[part 1 of 2: packages /Diagnostics/port_interfaces to /DataTypes/ImplementationDataTypes]
AUTOSAR XML (schema 00047)
standard types defined: boolean, uint16, uint32, uint64, uint8
package /Diagnostics/port_interfaces
  diagnostic condition interface Condition_Interface
  diagnostic dtc information interface DTC_Information_Interface
  diagnostic data identifier generic interface DataIdentifierGeneric_Interface
  diagnostic data identifier interface VersionInfoDataIdentifier
    namespaces:
      symbol props lorem
      symbol props ipsum
    read Read
      arg VersionInfoBuffer: type=ByteVector, direction=OUT
  diagnostic data identifier interface SystemInfoDataIdentifier
    namespaces:
      symbol props lorem
      symbol props ipsum
    read Read
      arg SystemInfoBuffer: type=ByteVector, direction=OUT
  diagnostic data identifier interface VINInformation_Interface
    read Read
      arg Vin: type=VINType, direction=OUT
    write Write
      arg Vin: type=VINType, direction=IN
  diagnostic do ip group identification interface DoIPGroupIdentification_Interface
  diagnostic do ip power mode interface DoIPPowerMode_Interface
  diagnostic download interface Download_Interface
  diagnostic event interface Event_Interface
  diagnostic generic uds interface Generic_Uds_Interface
  diagnostic indicator interface Indicator_Interface
  diagnostic monitor interface Monitor_Interface
  diagnostic operation cycle interface OperationCycle_Interface
  diagnostic routine generic interface RoutineGeneric_Interface
  diagnostic security level interface SecurityLevel_Interface
  diagnostic service validation interface ServiceValidation_Interface
  diagnostic upload interface Upload_Interface
package /Diagnostics/types
  11 x std cpp implementation data type, all with type-emitter=TYPE_EMITTER_ARA:
    VINType: category=ARRAY, array-size=17, cpp-template-argument=uint8_t  # 17 byte array of uint8 representing the VIN
      namespaces:
        symbol props ara
        symbol props diag
    ArrayBytes7: category=ARRAY, array-size=7, cpp-template-argument=uint8_t  # byte array of 7 bytes
      namespaces:
        symbol props self_diag_agent
    ByteVector: category=VECTOR, cpp-template-argument=uint8_t  # Vector of uint8
      namespaces:
        symbol props self_diag_agent
    InstanceHandle: type-reference=uint32_t
      namespaces:
        symbol props ns0: symbol=amsr
        symbol props ns1: symbol=diag
        symbol props ns2: symbol=com_api
    DiagRequestType: category=STRUCTURE
      namespaces:
        symbol props ns0: symbol=amsr
        symbol props ns1: symbol=diag
        symbol props ns2: symbol=com_api
      5 x cpp implementation data type element:
        handle: type-reference=HandleType
        instance_handle: type-reference=InstanceHandle
        conversation_handle: type-reference=ConversationHandle
        job_identifier: type-reference=JobIdentifier
        value: type-reference=ByteVectorType
    ConversationHandle: type-reference=uint16_t
      namespaces:
        symbol props ns0: symbol=amsr
        symbol props ns1: symbol=diag
        symbol props ns2: symbol=com_api
    HandleType: type-reference=uint16_t
      namespaces:
        symbol props ns0: symbol=amsr
        symbol props ns1: symbol=diag
        symbol props ns2: symbol=com_api
    MetaInfoType: category=ASSOCIATIVE_MAP, template-arguments=[string, string]  # Meta-Inf map, which contains key-value pairs of MetaInfoKeyType, MetaInfoValueType.
      namespaces:
        symbol props ns0: symbol=amsr
        symbol props ns1: symbol=diag
        symbol props ns2: symbol=com_api
    ByteVectorType: category=VECTOR, cpp-template-argument=uint8_t
      namespaces:
        symbol props ns0: symbol=amsr
        symbol props ns1: symbol=diag
        symbol props ns2: symbol=com_api
    JobIdentifier: type-reference=uint32_t
      namespaces:
        symbol props ns0: symbol=amsr
        symbol props ns1: symbol=diag
        symbol props ns2: symbol=com_api
    DaemonRequestResponseType: category=STRUCTURE
      namespaces:
        symbol props ns0: symbol=amsr
        symbol props ns1: symbol=diag
        symbol props ns2: symbol=com_api
      cpp implementation data type element response_type: type-reference=HandleType
      cpp implementation data type element job_identifier: type-reference=JobIdentifier
      cpp implementation data type element value: type-reference=ByteVectorType
package /Diagnostics/Persistency
  persistency file array Deamon_PersistencyFileArray: update-strategy=KEEP-EXISTING, uri=./etc/nv_data
  persistency file proxy interface PersistencyInterface: category=binary
  persistency port prototype to file array mapping PersistencyPortPrototypeToFileArrayMapping: persistency-file-array=Deamon_PersistencyFileArray, port-prototype=BaseApplicationExecutableRootSwc.Persistency, process=DiagnosticManagerDeamon
package /Application/AdaptiveApplicationSwComponentTypes
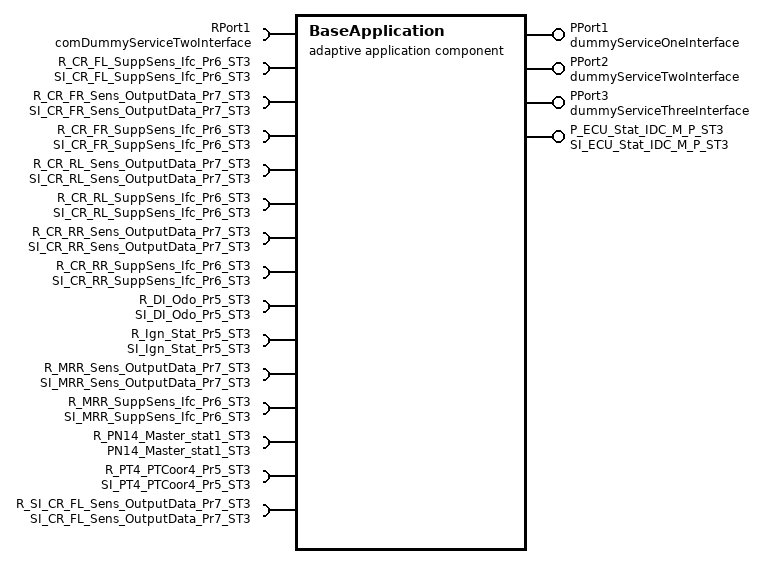
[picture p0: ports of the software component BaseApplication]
  adaptive application sw component type BaseApplication
    4 x provide port:
      PPort1: provided-interface=dummyServiceOneInterface
      PPort2: provided-interface=dummyServiceTwoInterface
      PPort3: provided-interface=dummyServiceThreeInterface
      P_ECU_Stat_IDC_M_P_ST3: provided-interface=SI_ECU_Stat_IDC_M_P_ST3
    provide/require port MyPersistencyKvsPrPortPrototype: provided-required-interface=IF_Persistency_KVS
    15 x require port:
      RPort1: required-interface=comDummyServiceTwoInterface
      R_CR_FL_SuppSens_Ifc_Pr6_ST3: required-interface=SI_CR_FL_SuppSens_Ifc_Pr6_ST3
      R_CR_FR_Sens_OutputData_Pr7_ST3: required-interface=SI_CR_FR_Sens_OutputData_Pr7_ST3
      R_CR_FR_SuppSens_Ifc_Pr6_ST3: required-interface=SI_CR_FR_SuppSens_Ifc_Pr6_ST3
      R_CR_RL_Sens_OutputData_Pr7_ST3: required-interface=SI_CR_RL_Sens_OutputData_Pr7_ST3
      R_CR_RL_SuppSens_Ifc_Pr6_ST3: required-interface=SI_CR_RL_SuppSens_Ifc_Pr6_ST3
      R_CR_RR_Sens_OutputData_Pr7_ST3: required-interface=SI_CR_RR_Sens_OutputData_Pr7_ST3
      R_CR_RR_SuppSens_Ifc_Pr6_ST3: required-interface=SI_CR_RR_SuppSens_Ifc_Pr6_ST3
      R_DI_Odo_Pr5_ST3: required-interface=SI_DI_Odo_Pr5_ST3
      R_Ign_Stat_Pr5_ST3: required-interface=SI_Ign_Stat_Pr5_ST3
      R_MRR_Sens_OutputData_Pr7_ST3: required-interface=SI_MRR_Sens_OutputData_Pr7_ST3
      R_MRR_SuppSens_Ifc_Pr6_ST3: required-interface=SI_MRR_SuppSens_Ifc_Pr6_ST3
      R_PN14_Master_stat1_ST3: required-interface=PN14_Master_stat1_ST3
      R_PT4_PTCoor4_Pr5_ST3: required-interface=SI_PT4_PTCoor4_Pr5_ST3
      R_SI_CR_FL_Sens_OutputData_Pr7_ST3: required-interface=SI_CR_FL_Sens_OutputData_Pr7_ST3
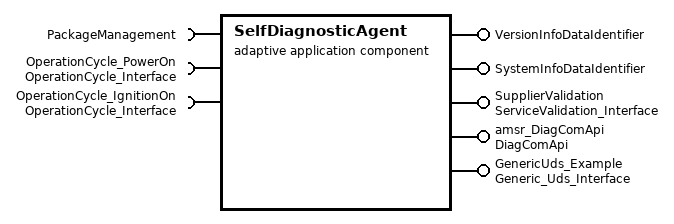
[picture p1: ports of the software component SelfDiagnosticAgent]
  adaptive application sw component type SelfDiagnosticAgent
    5 x provide port:
      VersionInfoDataIdentifier: provided-interface=VersionInfoDataIdentifier
      SystemInfoDataIdentifier: provided-interface=SystemInfoDataIdentifier
      SupplierValidation: provided-interface=ServiceValidation_Interface
      amsr_DiagComApi: provided-interface=DiagComApi
      GenericUds_Example: provided-interface=Generic_Uds_Interface
    require port PackageManagement: required-interface=PackageManagement
    require port OperationCycle_PowerOn: required-interface=OperationCycle_Interface
    require port OperationCycle_IgnitionOn: required-interface=OperationCycle_Interface
    adaptive swc internal behavior AdaptiveInternalBehavior
      6 x swc service dependency:
        SwcDependency_VersionInfoDataIdentifier_Port: assigned-ports=role-based-port-assignment={port-prototype=VersionInfoDataIdentifier, role=DataServices}
        SwcDependency_SystemInfoDataIdentifier_Port: assigned-ports=role-based-port-assignment={port-prototype=SystemInfoDataIdentifier, role=DataServices}
        OperationCyclePowerOn: assigned-ports=role-based-port-assignment={port-prototype=OperationCycle_PowerOn, role=SomeOtherRole}
        OperationCycleIgnitionOn: assigned-ports=role-based-port-assignment={port-prototype=OperationCycle_IgnitionOn, role=SomeOtherRole}
        SwcDependency_ServiceValidation_Supplier_Example: assigned-ports=role-based-port-assignment={port-prototype=SupplierValidation, role=ServiceValidation}
          service-needs:
            diagnostic communication manager needs Supplier: service-request-callback-type=REQUEST-CALLBACK-TYPE-SUPPLIER
        GenericUds_Example: assigned-ports=role-based-port-assignment={port-prototype=GenericUds_Example, role=SomeOtherRole}
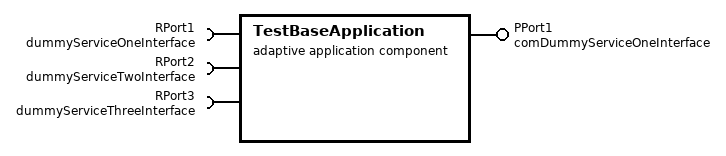
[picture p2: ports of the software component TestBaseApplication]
  adaptive application sw component type TestBaseApplication
    provide port PPort1: provided-interface=comDummyServiceOneInterface
    require port RPort1: required-interface=dummyServiceOneInterface
    require port RPort2: required-interface=dummyServiceTwoInterface
    require port RPort3: required-interface=dummyServiceThreeInterface
package /Application/Executables
  4 x executable, all with category=APPLICATION_LEVEL, version=1.00.00.0000:
    BaseApplicationExecutable: build-type=BUILD-TYPE-DEBUG
      root sw component prototype BaseApplicationExecutableRootSwc: application-type=BaseApplication
    SelfDiagnosticAgentExecutable: build-type=BUILD-TYPE-DEBUG
      root sw component prototype SelfDiagnosticAgentExecutableRootSwc: application-type=SelfDiagnosticAgent
    DiagnosticManagerDeamonExecutable
      root sw component prototype DiagnosticManagerDeamonExecutableRootSwc: application-type=DiagnosticManagerSwc
    TestBaseApplicationExecutable: build-type=BUILD-TYPE-DEBUG
      root sw component prototype TestBaseApplicationExecutableRootSwc: application-type=TestBaseApplication
package /ApplicationDeployment/Processes
  4 x process:
    BaseApplication: executable=BaseApplicationExecutable, state-dependent-startup-config{function-group-state=MachineState.Running, startup-config=STARTUP_CONFIG_DEFAULT}
      process state machine ProcessStateMachine_BaseApplication: type=MachineStates
    SelfDiagnosticAgent: executable=SelfDiagnosticAgentExecutable, state-dependent-startup-config{function-group-state=MachineState.Running, startup-config=STARTUP_CONFIG_DEFAULT}
    DiagnosticManagerDeamon: design=DiagnosticManagerDeamonDesign, executable=DiagnosticManagerDeamonExecutable, state-dependent-startup-config{function-group-state=[MachineState.Startup, MachineState.Running], startup-config=STARTUP_CONFIG_DEFAULT}
    TestBaseApplication: executable=TestBaseApplicationExecutable, state-dependent-startup-config{function-group-state=MachineState.Running, startup-config=STARTUP_CONFIG_DEFAULT}
      process state machine ModeDeclarationGroupElement21: type=MachineStates
package /ApplicationDeployment/ProcessDesigns
  process design DiagnosticManagerDeamonDesign: executable=DiagnosticManagerDeamonExecutable
  process design SelfDiagnosticAgentDesign: executable=SelfDiagnosticAgentExecutable
  process design BaseApplicationProcessDesign: executable=BaseApplicationExecutable
package /Communication/PDUs
  pdu DI_OdoSpeedometer_ST3: length=8, unused-bit-pattern=255
    signal CRC_DI_Odo_Pr5_ST3: start 0, 16 bit, little-endian, base-type=uint16, transfer-property=PENDING, to IDC_Adpative
    signal SQC_DI_Odo_Pr5_ST3: start 16, 8 bit, little-endian, base-type=uint8, transfer-property=PENDING, to IDC_Adpative
    signal Odo_ST3_DI_Odo_Pr5_ST3: start 24, 24 bit, little-endian, base-type=uint32, to IDC_Adpative
    mapping DI_Odo_Pr5_ST3: i-signal-group=DI_Odo_Pr5_ST3, transfer-property=TRIGGERED-ON-CHANGE
  pdu ECU_Stat_IDC_M_P_ST3: length=8, unused-bit-pattern=0
    signal ECU_Id_IDC_M_P_ST3: start 0, 12 bit, little-endian, base-type=uint16, transfer-property=PENDING
    signal NwId_Rsrv_ST3: start 12, 8 bit, little-endian, base-type=uint8, transfer-property=PENDING
    signal WakeupRsn_IDC_M_P_ST3: start 20, 10 bit, little-endian, system signal WakeupRsn_IDC_M_P_ST3_ECU_Stat_IDC_M_P_ST3_P_ECU_Stat_IDC_M_P_ST3_R_ECU_Stat_IDC_M_P_ST3, base-type=uint16, transfer-property=PENDING
    signal Awake_Diag_Actv_IDC_M_P_ST3: start 30, 1 bit, little-endian, base-type=uint8, transfer-property=PENDING
    signal Awake_NwStart_IDC_M_P_ST3: start 31, 1 bit, little-endian, base-type=boolean, transfer-property=PENDING
    signal Awake_HAD_Actv_IDC_M_P_ST3: start 32, 1 bit, little-endian, base-type=boolean, transfer-property=PENDING
    signal Awake_Ignition_On_IDC_M_P_ST3: start 33, 1 bit, little-endian, base-type=boolean, transfer-property=PENDING
    mapping ECU_Stat_IDC_M_P_ST3: i-signal-group=ECU_Stat_IDC_M_P_ST3, transfer-property=PENDING
  pdu Ign_Stat_ST3: length=4, unused-bit-pattern=255
    signal CRC_Ign_Stat_Pr5_ST3: start 0, 16 bit, little-endian, base-type=uint16, transfer-property=PENDING, to IDC_Adpative
    signal SQC_Ign_Stat_Pr5_ST3: start 16, 8 bit, little-endian, base-type=uint8, transfer-property=PENDING, to IDC_Adpative
    signal ISw_Stat_ST3: start 24, 3 bit, little-endian, base-type=uint8, to IDC_Adpative
    signal Veh_Op_Mode_ST3: start 27, 4 bit, little-endian, base-type=uint8, transfer-property=PENDING, to IDC_Adpative
    signal KG_StartSw_Psd_ST3: start 31, 1 bit, little-endian, base-type=boolean, transfer-property=PENDING, to IDC_Adpative
    mapping Ign_Stat_Pr5_ST3: i-signal-group=Ign_Stat_Pr5_ST3, transfer-property=TRIGGERED-ON-CHANGE
  pdu PN14_Master_stat1_ST3: length=8, unused-bit-pattern=255  # PN14_Master_Stat1_ST3
    signal PN14_TransMd_Stat_ST3: start 0, 2 bit, little-endian, base-type=uint8, transfer-property=PENDING, to IDC_Adpative
    signal PN14_DDP_Sw_Stat_ST3: start 2, 3 bit, little-endian, base-type=uint8, transfer-property=PENDING, to IDC_Adpative
    signal PN14_ProdMd_Stat_ST3: start 5, 3 bit, little-endian, base-type=uint8, transfer-property=PENDING, to IDC_Adpative
    signal PN14_ProdMd_BatStat_ST3: start 8, 7 bit, little-endian, base-type=uint8, transfer-property=PENDING, to IDC_Adpative
    signal PN14_SupBat_Stat_ST3: start 15, 7 bit, little-endian, base-type=uint8, transfer-property=PENDING, to IDC_Adpative
    signal PN14_SupBat_Volt_ST3: start 22, 10 bit, little-endian, base-type=uint16, transfer-property=PENDING, to IDC_Adpative
    signal PN14_SupBat_Curr_ST3: start 32, 13 bit, little-endian, base-type=uint16, transfer-property=PENDING, to IDC_Adpative
    signal PN14_SupBat_Temp_ST3: start 45, 8 bit, little-endian, base-type=uint8, transfer-property=PENDING, to IDC_Adpative
    signal PN14_PNSec_RechargeEnable_ST3: start 53, 2 bit, little-endian, base-type=uint8, transfer-property=PENDING, to IDC_Adpative
    signal PN14_ExtBat_Charge_Actv_ST3: start 55, 2 bit, little-endian, base-type=uint8, transfer-property=PENDING, to IDC_Adpative
    signal PN14_DDP_Sw2_Stat_ST3: start 57, 3 bit, little-endian, base-type=uint8, transfer-property=PENDING, to IDC_Adpative
    mapping PN14_Master_stat1_ST3: i-signal-group=PN14_Master_stat1_ST3, transfer-property=PENDING
  pdu PT4_PTCoor4_ST3: length=4, unused-bit-pattern=255
    signal CRC_PT4_PTCoor4_Pr5_ST3: start 0, 16 bit, little-endian, base-type=uint16, transfer-property=PENDING, to IDC_Adpative
    signal SQC_PT4_PTCoor4_Pr5_ST3: start 16, 8 bit, little-endian, base-type=uint8, transfer-property=PENDING, to IDC_Adpative
    signal PT4_PTCoor_PT_Rdy_ST3: start 24, 2 bit, little-endian, base-type=uint8, transfer-property=PENDING, to IDC_Adpative
    signal PT4_PTCoor_SSA_EngSp_ST3: start 26, 2 bit, little-endian, base-type=uint8, transfer-property=PENDING, to IDC_Adpative
    signal PT4_PTCoor_EngStartPN14_Stat_ST3: start 28, 3 bit, little-endian, base-type=uint8, to IDC_Adpative
    signal Rsrv1_PT4_PTCoor_PT_Rdy_Pr5_ST3: start 31, 1 bit, little-endian, base-type=uint8, transfer-property=PENDING, to IDC_Adpative
    mapping PT4_PTCoor4_Pr5_ST3: i-signal-group=PT4_PTCoor4_Pr5_ST3, transfer-property=TRIGGERED-ON-CHANGE
package /Communication/Signals
  5 x i signal group:
    DI_Odo_Pr5_ST3: i-signal=[CRC_DI_Odo_Pr5_ST3, Odo_ST3_DI_Odo_Pr5_ST3, SQC_DI_Odo_Pr5_ST3], system-signal-group=DI_Odo_Pr5_ST3
    ECU_Stat_IDC_M_P_ST3: i-signal=[Awake_Diag_Actv_IDC_M_P_ST3, Awake_HAD_Actv_IDC_M_P_ST3, Awake_Ignition_On_IDC_M_P_ST3, Awake_NwStart_IDC_M_P_ST3, ECU_Id_IDC_M_P_ST3, NwId_Rsrv_ST3, WakeupRsn_IDC_M_P_ST3], system-signal-group=ECU_Stat_IDC_M_P_ST3
    Ign_Stat_Pr5_ST3: i-signal=[CRC_Ign_Stat_Pr5_ST3, ISw_Stat_ST3, KG_StartSw_Psd_ST3, SQC_Ign_Stat_Pr5_ST3, Veh_Op_Mode_ST3], system-signal-group=Ign_Stat_Pr5_ST3
    PN14_Master_stat1_ST3: i-signal=[PN14_DDP_Sw2_Stat_ST3, PN14_DDP_Sw_Stat_ST3, PN14_ExtBat_Charge_Actv_ST3, PN14_PNSec_RechargeEnable_ST3, PN14_ProdMd_BatStat_ST3, PN14_ProdMd_Stat_ST3, PN14_SupBat_Curr_ST3, PN14_SupBat_Stat_ST3, PN14_SupBat_Temp_ST3, PN14_SupBat_Volt_ST3, PN14_TransMd_Stat_ST3], system-signal-group=PN14_Master_stat1_ST3
    PT4_PTCoor4_Pr5_ST3: i-signal=[CRC_PT4_PTCoor4_Pr5_ST3, PT4_PTCoor_EngStartPN14_Stat_ST3, PT4_PTCoor_PT_Rdy_ST3, PT4_PTCoor_SSA_EngSp_ST3, Rsrv1_PT4_PTCoor_PT_Rdy_Pr5_ST3, SQC_PT4_PTCoor4_Pr5_ST3], system-signal-group=PT4_PTCoor4_Pr5_ST3
package /DataTypes/ImplementationDataTypes
  796 x std cpp implementation data type:
    ARRAY_ELEMENT: type-emitter=TYPE_EMITTER_ARA, type-reference=c08_perc_0_100_1
      namespaces:
        symbol props CR_Types_Namespace
    ARRAY_ELEMENT1: type-emitter=TYPE_EMITTER_ARA, type-reference=REC_CR_RR_Segment_ST3
      namespaces:
        symbol props CR_Types_Namespace
    ARRAY_ELEMENT10: category=ARRAY, array-size=2000, cpp-template-argument=ARRAY_ELEMENT_DIM4, type-emitter=TYPE_EMITTER_ARA
      namespaces:
        symbol props CR_Types_Namespace
    ARRAY_ELEMENT11: category=ARRAY, array-size=2000, cpp-template-argument=ARRAY_ELEMENT_DIM3, type-emitter=TYPE_EMITTER_ARA
      namespaces:
        symbol props CR_Types_Namespace
    ARRAY_ELEMENT2: type-emitter=TYPE_EMITTER_ARA, type-reference=REC_CR_RL_Segment_ST3
      namespaces:
        symbol props CR_Types_Namespace
    ARRAY_ELEMENT3: type-emitter=TYPE_EMITTER_ARA, type-reference=REC_CR_FL_Segment_ST3
      namespaces:
        symbol props CR_Types_Namespace
    ARRAY_ELEMENT4: type-emitter=TYPE_EMITTER_ARA, type-reference=REC_MRR_Segment_ST3
      namespaces:
        symbol props CR_Types_Namespace
    ARRAY_ELEMENT5: type-emitter=TYPE_EMITTER_ARA, type-reference=DC_TGC_ProximityLvl
      namespaces:
        symbol props CR_Types_Namespace
    ARRAY_ELEMENT6: type-emitter=TYPE_EMITTER_ARA, type-reference=REC_CR_FR_Segment_ST3
      namespaces:
        symbol props CR_Types_Namespace
    ARRAY_ELEMENT7: category=ARRAY, array-size=2000, cpp-template-argument=ARRAY_ELEMENT_DIM, type-emitter=TYPE_EMITTER_ARA
      namespaces:
        symbol props CR_Types_Namespace
    ARRAY_ELEMENT8: category=ARRAY, array-size=2000, cpp-template-argument=ARRAY_ELEMENT_DIM1, type-emitter=TYPE_EMITTER_ARA
      namespaces:
        symbol props CR_Types_Namespace
    ARRAY_ELEMENT9: category=ARRAY, array-size=2000, cpp-template-argument=ARRAY_ELEMENT_DIM2, type-emitter=TYPE_EMITTER_ARA
      namespaces:
        symbol props CR_Types_Namespace
    ARRAY_ELEMENT_DIM: type-emitter=TYPE_EMITTER_ARA, type-reference=REC_CR_RR_Detection_ST3
      namespaces:
        symbol props CR_Types_Namespace
    ARRAY_ELEMENT_DIM1: type-emitter=TYPE_EMITTER_ARA, type-reference=REC_CR_FL_Detection_ST3
      namespaces:
        symbol props CR_Types_Namespace
    ARRAY_ELEMENT_DIM2: type-emitter=TYPE_EMITTER_ARA, type-reference=REC_CR_FR_Detection_ST3
      namespaces:
        symbol props CR_Types_Namespace
    ARRAY_ELEMENT_DIM3: type-emitter=TYPE_EMITTER_ARA, type-reference=REC_CR_RL_Detection_ST3
      namespaces:
        symbol props CR_Types_Namespace
    ARRAY_ELEMENT_DIM4: type-emitter=TYPE_EMITTER_ARA, type-reference=REC_MRR_Detection_ST3
      namespaces:
        symbol props CR_Types_Namespace
    ARR_08_perc_0_100_1_8: category=ARRAY, array-size=8, cpp-template-argument=ARRAY_ELEMENT, type-emitter=TYPE_EMITTER_ARA  # ARR_08_%_0-100_1_8
      namespaces:
        symbol props CR_Types_Namespace
    ARR_CR_FL_Detection_ST3: category=STRUCTURE, type-emitter=TYPE_EMITTER_ARA
      namespaces:
        symbol props CR_Types_Namespace
      cpp implementation data type element SIZE: is-optional=false, type-reference=SIZE4
      cpp implementation data type element ARRAY_ELEMENT: is-optional=false, type-reference=ARRAY_ELEMENT8
    ARR_CR_FL_Segment_ST3: category=ARRAY, array-size=32, cpp-template-argument=ARRAY_ELEMENT3, type-emitter=TYPE_EMITTER_ARA
      namespaces:
        symbol props CR_Types_Namespace
    ARR_CR_FR_Detection_ST3: category=STRUCTURE, type-emitter=TYPE_EMITTER_ARA
      namespaces:
        symbol props CR_Types_Namespace
      cpp implementation data type element SIZE: is-optional=false, type-reference=SIZE1
      cpp implementation data type element ARRAY_ELEMENT: is-optional=false, type-reference=ARRAY_ELEMENT9
    ARR_CR_FR_Segment_ST3: category=ARRAY, array-size=32, cpp-template-argument=ARRAY_ELEMENT6, type-emitter=TYPE_EMITTER_ARA
      namespaces:
        symbol props CR_Types_Namespace
    ARR_CR_RL_Detection_ST3: category=STRUCTURE, type-emitter=TYPE_EMITTER_ARA
      namespaces:
        symbol props CR_Types_Namespace
      cpp implementation data type element SIZE: is-optional=false, type-reference=SIZE3
      cpp implementation data type element ARRAY_ELEMENT: is-optional=false, type-reference=ARRAY_ELEMENT11
    ARR_CR_RL_Segment_ST3: category=ARRAY, array-size=32, cpp-template-argument=ARRAY_ELEMENT2, type-emitter=TYPE_EMITTER_ARA
      namespaces:
        symbol props CR_Types_Namespace
    ARR_CR_RR_Detection_ST3: category=STRUCTURE, type-emitter=TYPE_EMITTER_ARA
      namespaces:
        symbol props CR_Types_Namespace
      cpp implementation data type element SIZE: is-optional=false, type-reference=SIZE2
      cpp implementation data type element ARRAY_ELEMENT: is-optional=false, type-reference=ARRAY_ELEMENT7
    ARR_CR_RR_Segment_ST3: category=ARRAY, array-size=32, cpp-template-argument=ARRAY_ELEMENT1, type-emitter=TYPE_EMITTER_ARA
      namespaces:
        symbol props CR_Types_Namespace
    ARR_MRR_Detection_ST3: category=STRUCTURE, type-emitter=TYPE_EMITTER_ARA
      namespaces:
        symbol props CR_Types_Namespace
      cpp implementation data type element SIZE: is-optional=false, type-reference=SIZE
      cpp implementation data type element ARRAY_ELEMENT: is-optional=false, type-reference=ARRAY_ELEMENT10
    ARR_MRR_Segment_ST3: category=ARRAY, array-size=32, cpp-template-argument=ARRAY_ELEMENT4, type-emitter=TYPE_EMITTER_ARA
      namespaces:
        symbol props CR_Types_Namespace
    ARR_Stat_16_UInt_noSNA_100: category=ARRAY, array-size=100, cpp-template-argument{category=VALUE, template-type=uint16_t}, type-emitter=TYPE_EMITTER_ARA
      namespaces:
        symbol props ARR_Stat_16_UInt_noSNA_100
    ARR_Stat_REC_100: category=ARRAY, array-size=100, cpp-template-argument{category=STRUCTURE, template-type=REC_Uint8_Uint16_Uint16_AdAR}, type-emitter=TYPE_EMITTER_ARA
      namespaces:
        symbol props ARR_Stat_REC_100
    ARR_Stat_Uint16_100_Element_AdAR: type-emitter=TYPE_EMITTER_ARA, type-reference=ARR_Stat_16_UInt_noSNA_100
      namespaces:
        symbol props DataTypes
    Awake_Diag_Actv_IDC_M_P_ST3: type-emitter=TYPE_EMITTER_ARA, type-reference=uint8_t  # Sequence counter
      namespaces:
        symbol props TypeRef
    Awake_HAD_Actv_IDC_M_P_ST3: type-emitter=TYPE_EMITTER_ARA, type-reference=bool  # Operating Mode Vehicle
      namespaces:
        symbol props TypeRef
    Awake_Ignition_On_IDC_M_P_ST3: type-emitter=TYPE_EMITTER_ARA, type-reference=bool  # Operating Mode Vehicle
      namespaces:
        symbol props TypeRef
    Awake_NwStart_IDC_M_P_ST3: type-emitter=TYPE_EMITTER_ARA, type-reference=bool  # Keyless Go start switch pressed
      namespaces:
        symbol props TypeRef
    CRC_DI_Odo_Pr5_ST3: type-emitter=TYPE_EMITTER_ARA, type-reference=c16_CRC_woSNA  # CRC-checksum of signal group according to AUTOSAR Profile 5
      namespaces:
        symbol props TypeRef
    CRC_Ign_Stat_Pr5_ST3: type-emitter=TYPE_EMITTER_ARA, type-reference=c16_CRC_woSNA  # CRC-checksum of signal group according to AUTOSAR Profile 5
      namespaces:
        symbol props TypeRef
    CRC_PT4_PTCoor4_Pr5_ST3: type-emitter=TYPE_EMITTER_ARA, type-reference=c16_CRC_woSNA  # CRC-checksum of signal group according to AUTOSAR Profile 5
      namespaces:
        symbol props TypeRef
    CR_FL_AziAngl_LowLmt_ST3: type-emitter=TYPE_EMITTER_ARA, type-reference=c16_rad_m157_0_0d001  # Upper limit of the sensor's unambigious azimuth domain
      namespaces:
        symbol props CR_Types_Namespace
    CR_FL_AziAngl_UpLmt_ST3: type-emitter=TYPE_EMITTER_ARA, type-reference=c16_rad_0_1d57_0d001  # Lower limit of the sensor's unambigious azimuth domain
      namespaces:
        symbol props CR_Types_Namespace
    CR_FL_Cycl_Count_ST3: type-emitter=TYPE_EMITTER_ARA, type-reference=c64_0_0_1d84467E19_1_SNA  # Consecutive cycle count
      namespaces:
        symbol props CR_Types_Namespace
    CR_FL_Data_Qual_ST3: type-emitter=TYPE_EMITTER_ARA, type-reference=c08_Sens_Data_Qual_ST3  # Status ID representing the current quality level of the sensor
      namespaces:
        symbol props CR_Types_Namespace
    CR_FL_Detection_ST3: type-emitter=TYPE_EMITTER_ARA, type-reference=ARR_CR_FL_Detection_ST3
      namespaces:
        symbol props CR_Types_Namespace
    CR_FL_Dist_RadVelo_Cov_ST3: type-emitter=TYPE_EMITTER_ARA, type-reference=c08_m_sq_p_s_m0d01_p0d01_0d00008  # Covariance of the distance and radial velocity dimension
      namespaces:
        symbol props CR_Types_Namespace
    CR_FL_Dist_Range__ST3: type-emitter=TYPE_EMITTER_ARA, type-reference=c16_m_0_500_0d1  # Upper limit of the sensor's range ambiguity domain
      namespaces:
        symbol props CR_Types_Namespace
    CR_FL_Dtct_SNR_Err_ST3: type-emitter=TYPE_EMITTER_ARA, type-reference=c08_dB_0_5_0d02
      namespaces:
        symbol props CR_Types_Namespace
    CR_FL_Dtctn_Ambgt_ID_ST3: type-emitter=TYPE_EMITTER_ARA, type-reference=c16_0_3000_1
      namespaces:
        symbol props CR_Types_Namespace
    CR_FL_Dtctn_Ambgt_Probb_ST3: type-emitter=TYPE_EMITTER_ARA, type-reference=c08_perc_0_100_1
      namespaces:
        symbol props CR_Types_Namespace
    CR_FL_Dtctn_Azi_Qual_ST3: type-emitter=TYPE_EMITTER_ARA, type-reference=c08_0_100_1
      namespaces:
        symbol props CR_Types_Namespace
    CR_FL_Dtctn_Azi_ST3: type-emitter=TYPE_EMITTER_ARA, type-reference=c16_rad_m1d571_1d57_0d0001745
      namespaces:
        symbol props CR_Types_Namespace
    CR_FL_Dtctn_Azi_StdDev_ST3: type-emitter=TYPE_EMITTER_ARA, type-reference=c08_rad_0_0d044323_0d0001745
      namespaces:
        symbol props CR_Types_Namespace
    CR_FL_Dtctn_Dist_Qual_ST3: type-emitter=TYPE_EMITTER_ARA, type-reference=c08_0_100_1
      namespaces:
        symbol props CR_Types_Namespace
    CR_FL_Dtctn_Dist_ST3: type-emitter=TYPE_EMITTER_ARA, type-reference=c32_m_0_500_0d001
      namespaces:
        symbol props CR_Types_Namespace
    CR_FL_Dtctn_Dist_StdDev_ST3: type-emitter=TYPE_EMITTER_ARA, type-reference=c08_m_0_1d02_0d004_no_SNA
      namespaces:
        symbol props CR_Types_Namespace
    CR_FL_Dtctn_Elev_Qual_ST3: type-emitter=TYPE_EMITTER_ARA, type-reference=c08_0_100_1
      namespaces:
        symbol props CR_Types_Namespace
    CR_FL_Dtctn_Elev_ST3: type-emitter=TYPE_EMITTER_ARA, type-reference=c16_rad_m1d571_1d57_0d0001745
      namespaces:
        symbol props CR_Types_Namespace
    CR_FL_Dtctn_Elev_StdDev_ST3: type-emitter=TYPE_EMITTER_ARA, type-reference=c08_rad_0_0d0886714_0d0001745
      namespaces:
        symbol props CR_Types_Namespace
    CR_FL_Dtctn_Existence_Prob_ST3: type-emitter=TYPE_EMITTER_ARA, type-reference=c08_perc_0_100_1
      namespaces:
        symbol props CR_Types_Namespace
    CR_FL_Dtctn_FreeSp_Probb_ST3: type-emitter=TYPE_EMITTER_ARA, type-reference=c08_perc_0_100_1
      namespaces:
        symbol props CR_Types_Namespace
    CR_FL_Dtctn_ID_Part1_ST3: type-emitter=TYPE_EMITTER_ARA, type-reference=c64_0_0_1d84467E19_1_SNA
      namespaces:
        symbol props CR_Types_Namespace
    CR_FL_Dtctn_ID_Part2_ST3: type-emitter=TYPE_EMITTER_ARA, type-reference=c64_0_0_1d84467E19_1_SNA
      namespaces:
        symbol props CR_Types_Namespace
    CR_FL_Dtctn_MaskAnglSect_Azi_ST3: type-emitter=TYPE_EMITTER_ARA, type-reference=c08_rad_0_3d1416_0d01232_no_SNA
      namespaces:
        symbol props CR_Types_Namespace
    CR_FL_Dtctn_MaskAnglSect_Elev_ST3: type-emitter=TYPE_EMITTER_ARA, type-reference=c08_rad_0_3d1416_0d01232_no_SNA
      namespaces:
        symbol props CR_Types_Namespace
    CR_FL_Dtctn_Meas_Model_ST3: type-emitter=TYPE_EMITTER_ARA, type-reference=c08_Sens_MeasModel_ST3
      namespaces:
        symbol props CR_Types_Namespace
    CR_FL_Dtctn_Micro_Doppler_Val_ST3: type-emitter=TYPE_EMITTER_ARA, type-reference=c08_0_to_3_1_SNA_255
      namespaces:
        symbol props CR_Types_Namespace
    CR_FL_Dtctn_MultiTrgt_Probb_ST3: type-emitter=TYPE_EMITTER_ARA, type-reference=c08_perc_0_100_1
      namespaces:
        symbol props CR_Types_Namespace
    CR_FL_Dtctn_PeakDtct_Thrsld_ST3: type-emitter=TYPE_EMITTER_ARA, type-reference=c08_dB_0_20_0d1
      namespaces:
        symbol props CR_Types_Namespace
    CR_FL_Dtctn_RCS_Err_ST3: type-emitter=TYPE_EMITTER_ARA, type-reference=c08_dBsm_0_2d54_0d01
      namespaces:
        symbol props CR_Types_Namespace
    CR_FL_Dtctn_RCS_ST3: type-emitter=TYPE_EMITTER_ARA, type-reference=c16_dBsm_m100_p100_0d0035
      namespaces:
        symbol props CR_Types_Namespace
    CR_FL_Dtctn_RadRelVelo_Ambgt_Resolv_ST3: type-emitter=TYPE_EMITTER_ARA, type-reference=c02_Fls_Tru
      namespaces:
        symbol props CR_Types_Namespace
    CR_FL_Dtctn_RadRelVelo_ST3: type-emitter=TYPE_EMITTER_ARA, type-reference=c32_m_per_s_m200_100_0d001
      namespaces:
        symbol props CR_Types_Namespace
    CR_FL_Dtctn_RadRelVelo_StdDev_ST3: type-emitter=TYPE_EMITTER_ARA, type-reference=c08_m_p_s_0_0d663_0d0026_No_SNA
      namespaces:
        symbol props CR_Types_Namespace
    CR_FL_Dtctn_RadVelo_Qual_ST3: type-emitter=TYPE_EMITTER_ARA, type-reference=c08_0_100_1
      namespaces:
        symbol props CR_Types_Namespace
    CR_FL_Dtctn_RxSig_Strength_ST3: type-emitter=TYPE_EMITTER_ARA, type-reference=c08_dB_m254_0_1
      namespaces:
        symbol props CR_Types_Namespace
    CR_FL_Dtctn_SNR_ST3: type-emitter=TYPE_EMITTER_ARA, type-reference=c08_dB_0_50_0d2
      namespaces:
        symbol props CR_Types_Namespace
    CR_FL_Dtctn_Stat_ST3: type-emitter=TYPE_EMITTER_ARA, type-reference=c08_Sens_Dtctn_Stat_ST3  # Current status of the sensor. Each number corresponds to a specific state
      namespaces:
        symbol props CR_Types_Namespace
    CR_FL_Dtctn_StaticObj_Stat_ST3: type-emitter=TYPE_EMITTER_ARA, type-reference=c02_Fls_Tru
      namespaces:
        symbol props CR_Types_Namespace
    CR_FL_ElevAngl_LowLmt_ST3: type-emitter=TYPE_EMITTER_ARA, type-reference=c8_rad_m1d404_0_0d006  # Upper limit of the sensor's unambigious elevation domain
      namespaces:
        symbol props CR_Types_Namespace
    CR_FL_ElevAngl_UpLmt_ST3: type-emitter=TYPE_EMITTER_ARA, type-reference=c8_rad_0_1d404_0d006  # Lower limit of the sensor's unambigious elevation domain
      namespaces:
        symbol props CR_Types_Namespace
    CR_FL_Gen_Header_ST3: type-emitter=TYPE_EMITTER_ARA, type-reference=REC_CR_FL_Gen_Header_ST3
      namespaces:
        symbol props CR_Types_Namespace
    CR_FL_Interface_CyclTime_ST3: type-emitter=TYPE_EMITTER_ARA, type-reference=c32_ms_0_4294967294_1  # The current cycle time of the sensor
      namespaces:
        symbol props CR_Types_Namespace
    CR_FL_Interface_CyclTime_Var_ST3: type-emitter=TYPE_EMITTER_ARA, type-reference=c08_perc_0_100_1  # The current variation of the cycle time of the sensor
      namespaces:
        symbol props CR_Types_Namespace
    CR_FL_Interface_ID_ST3: type-emitter=TYPE_EMITTER_ARA, type-reference=c08_0_254_1  # Radar interface ID
      namespaces:
        symbol props CR_Types_Namespace
    CR_FL_LowDist_Dtctn_Indicator_ST3: type-emitter=TYPE_EMITTER_ARA, type-reference=c08_perc_0_100_1  # Probability of a low distance detection
      namespaces:
        symbol props CR_Types_Namespace
    CR_FL_MaxDtctn_ST3: type-emitter=TYPE_EMITTER_ARA, type-reference=c16_0_6000_1  # Maximum number of detections that could be processed by the sensor
      namespaces:
        symbol props CR_Types_Namespace
    CR_FL_Meas_Dur_ST3: type-emitter=TYPE_EMITTER_ARA, type-reference=c16_ms_0_65534_1  # Duration of the measurement time period of this frame
      namespaces:
        symbol props CR_Types_Namespace
    CR_FL_Meas_TmStmp_ST3: type-emitter=TYPE_EMITTER_ARA, type-reference=c64_ms_1_1d84467E19_1  # Timestamp of this measurment
      namespaces:
        symbol props CR_Types_Namespace
    CR_FL_Moduln_Md_ST3: type-emitter=TYPE_EMITTER_ARA, type-reference=c08_Sens_Moduln_Md_ST3  # Current modulation mode of the sensor. Each number corresponds to a specific state
      namespaces:
        symbol props CR_Types_Namespace
    CR_FL_RadVelo_LowLmt_ST3: type-emitter=TYPE_EMITTER_ARA, type-reference=c16_m_per_s_m130_0_0d01  # Lower limit of the sensor's unambigious radial velocity range
      namespaces:
        symbol props CR_Types_Namespace
    CR_FL_RadVelo_UpLmt_ST3: type-emitter=TYPE_EMITTER_ARA, type-reference=c16_m_per_s_0_130_0d01  # Upper limit of the sensor's unambigious radial velocity range
      namespaces:
        symbol props CR_Types_Namespace
    CR_FL_Radar_Header_ST3: type-emitter=TYPE_EMITTER_ARA, type-reference=REC_CR_FL_Radar_Header_ST3
      namespaces:
        symbol props CR_Types_Namespace
    CR_FL_SHI_Header_ST3: type-emitter=TYPE_EMITTER_ARA, type-reference=REC_CR_FL_SHI_Header_ST3  # Radar SHI Header
      namespaces:
        symbol props CR_Types_Namespace
    CR_FL_SPI_Header_ST3: type-emitter=TYPE_EMITTER_ARA, type-reference=REC_CR_FL_SPI_Header_ST3  # Sensor Performance Interface Header
      namespaces:
        symbol props CR_Types_Namespace
    CR_FL_SW_VerID_Major_ST3: type-emitter=TYPE_EMITTER_ARA, type-reference=c08_0_254_1  # Sensor software version ID major
      namespaces:
        symbol props CR_Types_Namespace
    CR_FL_SW_VerID_Minor_ST3: type-emitter=TYPE_EMITTER_ARA, type-reference=c08_0_254_1  # Sensor software version ID minor
      namespaces:
        symbol props CR_Types_Namespace
    CR_FL_SW_VerID_Patch_ST3: type-emitter=TYPE_EMITTER_ARA, type-reference=c08_0_254_1  # Sensor software version ID patch
      namespaces:
        symbol props CR_Types_Namespace
    CR_FL_Seg_AziAngl_Begin_ST3: type-emitter=TYPE_EMITTER_ARA, type-reference=c10_deg_m180_180_1  # Begin of segment in azimuth
      namespaces:
        symbol props CR_Types_Namespace
    CR_FL_Seg_AziAngl_End_ST3: type-emitter=TYPE_EMITTER_ARA, type-reference=c10_deg_m180_180_1  # End of segment in azimuth
      namespaces:
        symbol props CR_Types_Namespace
    CR_FL_Seg_Blockage_Stat_ST3: type-emitter=TYPE_EMITTER_ARA, type-reference=c03_SegBlock_Stat_ST3  # Segment blockage information
      namespaces:
        symbol props CR_Types_Namespace
    CR_FL_Seg_DetctnRange_Max_ST3: type-emitter=TYPE_EMITTER_ARA, type-reference=c10_m_0_400_0d5  # Maximum real detection range based on reference target
      namespaces:
        symbol props CR_Types_Namespace
    CR_FL_Seg_DetctnRange_Min_ST3: type-emitter=TYPE_EMITTER_ARA, type-reference=c10_m_0_400_0d5  # Minimum real detection range based on reference target
      namespaces:
        symbol props CR_Types_Namespace
    CR_FL_Seg_ElevAngl_Begin_ST3: type-emitter=TYPE_EMITTER_ARA, type-reference=c10_deg_m180_180_1  # Begin of segment in elevation
      namespaces:
        symbol props CR_Types_Namespace
    CR_FL_Seg_ElevAngl_End_ST3: type-emitter=TYPE_EMITTER_ARA, type-reference=c10_deg_m180_180_1  # End of segement in elevation
      namespaces:
        symbol props CR_Types_Namespace
    CR_FL_Seg_ID_ST3: type-emitter=TYPE_EMITTER_ARA, type-reference=c06_0_32_1  # Unique segment ID
      namespaces:
        symbol props CR_Types_Namespace
    CR_FL_Seg_Range_Gain_RCS_ST3: type-emitter=TYPE_EMITTER_ARA, type-reference=c10_dB_m30_30_0d1  # Reference RCS for reference target
      namespaces:
        symbol props CR_Types_Namespace
    CR_FL_Seg_Range_Gain_ST3: type-emitter=TYPE_EMITTER_ARA, type-reference=c07_perc_0_100_1  # Range gain for segment based on reference target
      namespaces:
        symbol props CR_Types_Namespace
    CR_FL_Seg_Redctn_Rsn_Prob_ST3: type-emitter=TYPE_EMITTER_ARA, type-reference=ARR_08_perc_0_100_1_8  # Segment probability for reason for blockage
      namespaces:
        symbol props CR_Types_Namespace
    CR_FL_Seg_Redctn_Rsn_ST3: type-emitter=TYPE_EMITTER_ARA, type-reference=c03_Seg_Reduction_Rsn_ST3  # Segment reason for blockage
      namespaces:
        symbol props CR_Types_Namespace
    CR_FL_Segment_ST3: type-emitter=TYPE_EMITTER_ARA, type-reference=ARR_CR_FL_Segment_ST3  # Radar Segments
      namespaces:
        symbol props CR_Types_Namespace
    CR_FL_Sens_COS_Offset_X_ST3: type-emitter=TYPE_EMITTER_ARA, type-reference=c08_m_0_2k5_0k01_NACPT_ST3  # Sensor coordinate system offset between mounting and antenna plane in x
      namespaces:
        symbol props CR_Types_Namespace
    CR_FL_Sens_COS_Offset_Y_ST3: type-emitter=TYPE_EMITTER_ARA, type-reference=c08_m_0_2k5_0k01_NACPT_ST3  # Sensor coordinate system offset between mounting and antenna plane in y
      namespaces:
        symbol props CR_Types_Namespace
    CR_FL_Sens_COS_Offset_Z_ST3: type-emitter=TYPE_EMITTER_ARA, type-reference=c08_m_0_2k5_0k01_NACPT_ST3  # Sensor coordinate system offset between mounting and antenna plane in z
      namespaces:
        symbol props CR_Types_Namespace
    CR_FL_Sens_Calib_Base_Stat_ST3: type-emitter=TYPE_EMITTER_ARA, type-reference=c02_Sens_Calib_Base_Stat_ST3  # Calibration Base State
      namespaces:
        symbol props CR_Types_Namespace
    CR_FL_Sens_Calib_Corrctn_LowLmt_Azi_ST3: type-emitter=TYPE_EMITTER_ARA, type-reference=c08_deg_m10_p10_0d1_ST3  # Lower limit of correction range in azimuth
      namespaces:
        symbol props CR_Types_Namespace
    CR_FL_Sens_Calib_Corrctn_LowLmt_Elev_ST3: type-emitter=TYPE_EMITTER_ARA, type-reference=c08_deg_m10_p10_0d1_ST3  # Lower limit of correction range in elevation
      namespaces:
        symbol props CR_Types_Namespace
    CR_FL_Sens_Calib_Corrctn_LowLmt_Roll_ST3: type-emitter=TYPE_EMITTER_ARA, type-reference=c08_deg_m10_p10_0d1_ST3  # Lower limit of correction range in elevation
      namespaces:
        symbol props CR_Types_Namespace
    CR_FL_Sens_Calib_Corrctn_Orient_Azi_ST3: type-emitter=TYPE_EMITTER_ARA, type-reference=c08_deg_m10_p10_0d1_ST3  # Current sensor mounting after correction in azimuth
      namespaces:
        symbol props CR_Types_Namespace
    CR_FL_Sens_Calib_Corrctn_Orient_Elev_ST3: type-emitter=TYPE_EMITTER_ARA, type-reference=c08_deg_m10_p10_0d1_ST3  # Current sensor mounting after correction in elevation
      namespaces:
        symbol props CR_Types_Namespace
    CR_FL_Sens_Calib_Corrctn_Orient_Roll_ST3: type-emitter=TYPE_EMITTER_ARA, type-reference=c08_deg_m10_p10_0d1_ST3  # Current sensor mounting after correction in roll
      namespaces:
        symbol props CR_Types_Namespace
    CR_FL_Sens_Calib_Corrctn_UpLmt_Azi_ST3: type-emitter=TYPE_EMITTER_ARA, type-reference=c08_deg_m10_p10_0d1_ST3  # Upper limit of correction range in azimuth
      namespaces:
        symbol props CR_Types_Namespace
    CR_FL_Sens_Calib_Corrctn_UpLmt_Elev_ST3: type-emitter=TYPE_EMITTER_ARA, type-reference=c08_deg_m10_p10_0d1_ST3  # Upper limit of correction range in elevation
      namespaces:
        symbol props CR_Types_Namespace
    CR_FL_Sens_Calib_Corrctn_UpLmt_Roll_ST3: type-emitter=TYPE_EMITTER_ARA, type-reference=c08_deg_m10_p10_0d1_ST3  # Upper limit of correction range in roll
      namespaces:
        symbol props CR_Types_Namespace
    CR_FL_Sens_Calib_Func_Stat_ST3: type-emitter=TYPE_EMITTER_ARA, type-reference=c04_Sens_Calib_Func_Stat_ST3  # Calibration Function State
      namespaces:
        symbol props CR_Types_Namespace
    CR_FL_Sens_Calib_SOC_Stat_ST3: type-emitter=TYPE_EMITTER_ARA, type-reference=c02_Sens_Calib_SOC_Stat_ST3  # Sustained Online Calibration State
      namespaces:
        symbol props CR_Types_Namespace
    CR_FL_Sens_Calib_Valid_Comp_ST3: type-emitter=TYPE_EMITTER_ARA, type-reference=c04_0_15_1_SNA_na  # Number of valid sensor calibration components
      namespaces:
        symbol props CR_Types_Namespace
    CR_FL_Sens_Defect_Dtct_ST3: type-emitter=TYPE_EMITTER_ARA, type-reference=c02_Sens_Defect_Dtct_ST3  # Defect state of sensor
      namespaces:
        symbol props CR_Types_Namespace
    CR_FL_Sens_Defect_Rsn_ST3: type-emitter=TYPE_EMITTER_ARA, type-reference=c03_Sens_Defect_Rsn_ST3  # Reasons of sensor defect
      namespaces:
        symbol props CR_Types_Namespace
    CR_FL_Sens_Diag_Md_ST3: type-emitter=TYPE_EMITTER_ARA, type-reference=c02_Diag_Mode_ST3  # State of sensor diagnostic interface
      namespaces:
        symbol props CR_Types_Namespace
    CR_FL_Sens_Extern_Disturbnc_ST3: type-emitter=TYPE_EMITTER_ARA, type-reference=c02_Sens_Disturbnc_Stat_ST3  # Status of disturbance by electromagentic phenomenon (interference)
      namespaces:
        symbol props CR_Types_Namespace
    CR_FL_Sens_GTS_Offset_ST3: type-emitter=TYPE_EMITTER_ARA, type-reference=c32_ns_0_4294967295_1_noSNA  # Offset time of GTS
      namespaces:
        symbol props CR_Types_Namespace
    CR_FL_Sens_Oprtn_Md_ST3: type-emitter=TYPE_EMITTER_ARA, type-reference=c02_Sens_Oprtn_Md_ST3  # Measuring state of sensor
      namespaces:
        symbol props CR_Types_Namespace
    CR_FL_Sens_Oprtn_Stat_ST3: type-emitter=TYPE_EMITTER_ARA, type-reference=c02_Sens_Oprtn_Stat_ST3  # Overall state of sensor health
      namespaces:
        symbol props CR_Types_Namespace
    CR_FL_Sens_Orient_Azi_ST3: type-emitter=TYPE_EMITTER_ARA, type-reference=c08_deg_m10_p10_0d1_ST3  # Sensor mounting orientation in azimuth
      namespaces:
        symbol props CR_Types_Namespace
    CR_FL_Sens_Orient_Elev_ST3: type-emitter=TYPE_EMITTER_ARA, type-reference=c08_deg_m10_p10_0d1_ST3  # Sensor mounting orientation in elevation
      namespaces:
        symbol props CR_Types_Namespace
    CR_FL_Sens_Orient_Err_Azi_ST3: type-emitter=TYPE_EMITTER_ARA, type-reference=c08_deg_m10_p10_0d1_ST3  # Sensor mounting orientation error in azimuth
      namespaces:
        symbol props CR_Types_Namespace
    CR_FL_Sens_Orient_Err_Elev_ST3: type-emitter=TYPE_EMITTER_ARA, type-reference=c08_deg_m10_p10_0d1_ST3  # Sensor mounting orientation error in elevation
      namespaces:
        symbol props CR_Types_Namespace
    CR_FL_Sens_Orient_Err_Roll_ST3: type-emitter=TYPE_EMITTER_ARA, type-reference=c08_deg_m10_p10_0d1_ST3  # Sensor mounting orientation error in roll
      namespaces:
        symbol props CR_Types_Namespace
    CR_FL_Sens_Orient_Roll_ST3: type-emitter=TYPE_EMITTER_ARA, type-reference=c08_deg_m10_p10_0d1_ST3  # Sensor mounting orientation in roll
      namespaces:
        symbol props CR_Types_Namespace
    CR_FL_Sens_Origin_Pos_Err_X_ST3: type-emitter=TYPE_EMITTER_ARA, type-reference=c08_m_0_2k5_0k01_NACPT_ST3  # Sensor mounting position error in x
      namespaces:
        symbol props CR_Types_Namespace
    CR_FL_Sens_Origin_Pos_Err_Y_ST3: type-emitter=TYPE_EMITTER_ARA, type-reference=c08_m_0_2k5_0k01_NACPT_ST3  # Sensor mounting position error in y
      namespaces:
        symbol props CR_Types_Namespace
    CR_FL_Sens_Origin_Pos_Err_Z_ST3: type-emitter=TYPE_EMITTER_ARA, type-reference=c08_m_0_2k5_0k01_NACPT_ST3  # Sensor mounting position error in z
      namespaces:
        symbol props CR_Types_Namespace
    CR_FL_Sens_Origin_Pos_X_ST3: type-emitter=TYPE_EMITTER_ARA, type-reference=c08_m_0_2k5_0k01_NACPT_ST3  # Sensor mounting position in x
      namespaces:
        symbol props CR_Types_Namespace
    CR_FL_Sens_Origin_Pos_Y_ST3: type-emitter=TYPE_EMITTER_ARA, type-reference=c08_m_0_2k5_0k01_NACPT_ST3  # Sensor mounting position in y
      namespaces:
        symbol props CR_Types_Namespace
    CR_FL_Sens_Origin_Pos_Z_ST3: type-emitter=TYPE_EMITTER_ARA, type-reference=c08_m_0_2k5_0k01_NACPT_ST3  # Sensor mounting position in z
      namespaces:
        symbol props CR_Types_Namespace
    CR_FL_Sens_Radom_Heat_Stat_ST3: type-emitter=TYPE_EMITTER_ARA, type-reference=c02_Sens_Radom_Heat_Stat_ST3  # Status of radom heating driver
      namespaces:
        symbol props CR_Types_Namespace
    CR_FL_Sens_Supp_Vtg_Stat_ST3: type-emitter=TYPE_EMITTER_ARA, type-reference=c02_Sens_SuppVtg_Stat_ST3  # State of supply voltage
      namespaces:
        symbol props CR_Types_Namespace
    CR_FL_Sens_Temp_Stat_ST3: type-emitter=TYPE_EMITTER_ARA, type-reference=c02_Sens_Temp_Stat_ST3  # State of internal sensor ECU temperature
      namespaces:
        symbol props CR_Types_Namespace
    CR_FL_Sens_TmSync_Stat_ST3: type-emitter=TYPE_EMITTER_ARA, type-reference=c02_Sens_TimeSync_Stat_ST3  # Status of GTS time sync
      namespaces:
        symbol props CR_Types_Namespace
    CR_FL_Sens_Total_Seg_Azi_ST3: type-emitter=TYPE_EMITTER_ARA, type-reference=c06_0_32_1  # Total (valid + invalid) number of segments in azimuth
      namespaces:
        symbol props CR_Types_Namespace
    CR_FL_Sens_Total_Seg_Elev_ST3: type-emitter=TYPE_EMITTER_ARA, type-reference=c06_0_32_1  # Total (valid + invalid) number of segments in elevation
      namespaces:
        symbol props CR_Types_Namespace
    CR_FL_Sens_Tx_PwrRedctn_Stat_ST3: type-emitter=TYPE_EMITTER_ARA, type-reference=c02_Sens_TxPwrRedctn_Stat_ST3  # Status of RF transmission
      namespaces:
        symbol props CR_Types_Namespace
    CR_FL_Sens_Valid_InputSignals_Curr_ST3: type-emitter=TYPE_EMITTER_ARA, type-reference=c08_UInt_SNA_na  # Number of currently valid input signals
      namespaces:
        symbol props CR_Types_Namespace
    CR_FL_Sens_Valid_InputSignals_Trgt_ST3: type-emitter=TYPE_EMITTER_ARA, type-reference=c08_UInt_SNA_na  # Number of target valid input signals
      namespaces:
        symbol props CR_Types_Namespace
    CR_FL_Sens_Valid_Seg_Azi_ST3: type-emitter=TYPE_EMITTER_ARA, type-reference=c06_0_32_1  # Valid number of segments in azimuth
      namespaces:
        symbol props CR_Types_Namespace
    CR_FL_Sens_Valid_Seg_Elev_ST3: type-emitter=TYPE_EMITTER_ARA, type-reference=c06_0_32_1  # Valid number of segments in elevation
      namespaces:
        symbol props CR_Types_Namespace
    CR_FL_SensorID_ST3: type-emitter=TYPE_EMITTER_ARA, type-reference=c08_0_254_1  # Sensor ID
      namespaces:
        symbol props CR_Types_Namespace
    CR_FL_ValidDtctn_ST3: type-emitter=TYPE_EMITTER_ARA, type-reference=c16_0_6000_1  # Number of valid detections in this measurement
      namespaces:
        symbol props CR_Types_Namespace
    CR_FR_AziAngl_LowLmt_ST3: type-emitter=TYPE_EMITTER_ARA, type-reference=c16_rad_m157_0_0d001  # Upper limit of the sensor's unambigious azimuth domain
      namespaces:
        symbol props CR_Types_Namespace
    CR_FR_AziAngl_UpLmt_ST3: type-emitter=TYPE_EMITTER_ARA, type-reference=c16_rad_0_1d57_0d001  # Lower limit of the sensor's unambigious azimuth domain
      namespaces:
        symbol props CR_Types_Namespace
    CR_FR_Cycl_Count_ST3: type-emitter=TYPE_EMITTER_ARA, type-reference=c64_0_0_1d84467E19_1_SNA  # Consecutive cycle count
      namespaces:
        symbol props CR_Types_Namespace
    CR_FR_Data_Qual_ST3: type-emitter=TYPE_EMITTER_ARA, type-reference=c08_Sens_Data_Qual_ST3  # Status ID representing the current quality level of the sensor
      namespaces:
        symbol props CR_Types_Namespace
    CR_FR_Detection_ST3: type-emitter=TYPE_EMITTER_ARA, type-reference=ARR_CR_FR_Detection_ST3
      namespaces:
        symbol props CR_Types_Namespace
    CR_FR_Dist_RadVelo_Cov_ST3: type-emitter=TYPE_EMITTER_ARA, type-reference=c08_m_sq_p_s_m0d01_p0d01_0d00008  # Covariance of the distance and radial velocity dimension
      namespaces:
        symbol props CR_Types_Namespace
    CR_FR_Dist_Range__ST3: type-emitter=TYPE_EMITTER_ARA, type-reference=c16_m_0_500_0d1  # Upper limit of the sensor's range ambiguity domain
      namespaces:
        symbol props CR_Types_Namespace
    CR_FR_Dtct_SNR_Err_ST3: type-emitter=TYPE_EMITTER_ARA, type-reference=c08_dB_0_5_0d02
      namespaces:
        symbol props CR_Types_Namespace
    CR_FR_Dtctn_Ambgt_ID_ST3: type-emitter=TYPE_EMITTER_ARA, type-reference=c16_0_3000_1
      namespaces:
        symbol props CR_Types_Namespace
    CR_FR_Dtctn_Ambgt_Probb_ST3: type-emitter=TYPE_EMITTER_ARA, type-reference=c08_perc_0_100_1
      namespaces:
        symbol props CR_Types_Namespace
    CR_FR_Dtctn_Azi_Qual_ST3: type-emitter=TYPE_EMITTER_ARA, type-reference=c08_0_100_1
      namespaces:
        symbol props CR_Types_Namespace
    CR_FR_Dtctn_Azi_ST3: type-emitter=TYPE_EMITTER_ARA, type-reference=c16_rad_m1d571_1d57_0d0001745
      namespaces:
        symbol props CR_Types_Namespace
    CR_FR_Dtctn_Azi_StdDev_ST3: type-emitter=TYPE_EMITTER_ARA, type-reference=c08_rad_0_0d044323_0d0001745
      namespaces:
        symbol props CR_Types_Namespace
    CR_FR_Dtctn_Dist_Qual_ST3: type-emitter=TYPE_EMITTER_ARA, type-reference=c08_0_100_1
      namespaces:
        symbol props CR_Types_Namespace
    CR_FR_Dtctn_Dist_ST3: type-emitter=TYPE_EMITTER_ARA, type-reference=c32_m_0_500_0d001
      namespaces:
        symbol props CR_Types_Namespace
    CR_FR_Dtctn_Dist_StdDev_ST3: type-emitter=TYPE_EMITTER_ARA, type-reference=c08_m_0_1d02_0d004_no_SNA
      namespaces:
        symbol props CR_Types_Namespace
    CR_FR_Dtctn_Elev_Qual_ST3: type-emitter=TYPE_EMITTER_ARA, type-reference=c08_0_100_1
      namespaces:
        symbol props CR_Types_Namespace
    CR_FR_Dtctn_Elev_ST3: type-emitter=TYPE_EMITTER_ARA, type-reference=c16_rad_m1d571_1d57_0d0001745
      namespaces:
        symbol props CR_Types_Namespace
    CR_FR_Dtctn_Elev_StdDev_ST3: type-emitter=TYPE_EMITTER_ARA, type-reference=c08_rad_0_0d0886714_0d0001745
      namespaces:
        symbol props CR_Types_Namespace
    CR_FR_Dtctn_Existence_Prob_ST3: type-emitter=TYPE_EMITTER_ARA, type-reference=c08_perc_0_100_1
      namespaces:
        symbol props CR_Types_Namespace
    CR_FR_Dtctn_FreeSp_Probb_ST3: type-emitter=TYPE_EMITTER_ARA, type-reference=c08_perc_0_100_1
      namespaces:
        symbol props CR_Types_Namespace
    CR_FR_Dtctn_ID_Part1_ST3: type-emitter=TYPE_EMITTER_ARA, type-reference=c64_0_0_1d84467E19_1_SNA
      namespaces:
        symbol props CR_Types_Namespace
    CR_FR_Dtctn_ID_Part2_ST3: type-emitter=TYPE_EMITTER_ARA, type-reference=c64_0_0_1d84467E19_1_SNA
      namespaces:
        symbol props CR_Types_Namespace
    CR_FR_Dtctn_MaskAnglSect_Azi_ST3: type-emitter=TYPE_EMITTER_ARA, type-reference=c08_rad_0_3d1416_0d01232_no_SNA
      namespaces:
        symbol props CR_Types_Namespace
    CR_FR_Dtctn_MaskAnglSect_Elev_ST3: type-emitter=TYPE_EMITTER_ARA, type-reference=c08_rad_0_3d1416_0d01232_no_SNA
      namespaces:
        symbol props CR_Types_Namespace
    CR_FR_Dtctn_Meas_Model_ST3: type-emitter=TYPE_EMITTER_ARA, type-reference=c08_Sens_MeasModel_ST3
      namespaces:
        symbol props CR_Types_Namespace
    CR_FR_Dtctn_Micro_Doppler_Val_ST3: type-emitter=TYPE_EMITTER_ARA, type-reference=c08_0_to_3_1_SNA_255
      namespaces:
        symbol props CR_Types_Namespace
    CR_FR_Dtctn_MultiTrgt_Probb_ST3: type-emitter=TYPE_EMITTER_ARA, type-reference=c08_perc_0_100_1
      namespaces:
        symbol props CR_Types_Namespace
    CR_FR_Dtctn_PeakDtct_Thrsld_ST3: type-emitter=TYPE_EMITTER_ARA, type-reference=c08_dB_0_20_0d1
      namespaces:
        symbol props CR_Types_Namespace
    CR_FR_Dtctn_RCS_Err_ST3: type-emitter=TYPE_EMITTER_ARA, type-reference=c08_dBsm_0_2d54_0d01
      namespaces:
        symbol props CR_Types_Namespace
    CR_FR_Dtctn_RCS_ST3: type-emitter=TYPE_EMITTER_ARA, type-reference=c16_dBsm_m100_p100_0d0035
      namespaces:
        symbol props CR_Types_Namespace
    CR_FR_Dtctn_RadRelVelo_Ambgt_Resolv_ST3: type-emitter=TYPE_EMITTER_ARA, type-reference=c02_Fls_Tru
      namespaces:
        symbol props CR_Types_Namespace
    CR_FR_Dtctn_RadRelVelo_ST3: type-emitter=TYPE_EMITTER_ARA, type-reference=c32_m_per_s_m200_100_0d001
      namespaces:
        symbol props CR_Types_Namespace
    CR_FR_Dtctn_RadRelVelo_StdDev_ST3: type-emitter=TYPE_EMITTER_ARA, type-reference=c08_m_p_s_0_0d663_0d0026_No_SNA
      namespaces:
        symbol props CR_Types_Namespace
    CR_FR_Dtctn_RadVelo_Qual_ST3: type-emitter=TYPE_EMITTER_ARA, type-reference=c08_0_100_1
      namespaces:
        symbol props CR_Types_Namespace
    CR_FR_Dtctn_RxSig_Strength_ST3: type-emitter=TYPE_EMITTER_ARA, type-reference=c08_dB_m254_0_1
      namespaces:
        symbol props CR_Types_Namespace
    CR_FR_Dtctn_SNR_ST3: type-emitter=TYPE_EMITTER_ARA, type-reference=c08_dB_0_50_0d2
      namespaces:
        symbol props CR_Types_Namespace
    CR_FR_Dtctn_Stat_ST3: type-emitter=TYPE_EMITTER_ARA, type-reference=c08_Sens_Dtctn_Stat_ST3  # Current status of the sensor. Each number corresponds to a specific state
      namespaces:
        symbol props CR_Types_Namespace
    CR_FR_Dtctn_StaticObj_Stat_ST3: type-emitter=TYPE_EMITTER_ARA, type-reference=c02_Fls_Tru
      namespaces:
        symbol props CR_Types_Namespace
    CR_FR_ElevAngl_LowLmt_ST3: type-emitter=TYPE_EMITTER_ARA, type-reference=c8_rad_m1d404_0_0d006  # Upper limit of the sensor's unambigious elevation domain
      namespaces:
        symbol props CR_Types_Namespace
    CR_FR_ElevAngl_UpLmt_ST3: type-emitter=TYPE_EMITTER_ARA, type-reference=c8_rad_0_1d404_0d006  # Lower limit of the sensor's unambigious elevation domain
      namespaces:
        symbol props CR_Types_Namespace
    CR_FR_Gen_Header_ST3: type-emitter=TYPE_EMITTER_ARA, type-reference=REC_CR_FR_Gen_Header_ST3
      namespaces:
        symbol props CR_Types_Namespace
    CR_FR_Interface_CyclTime_ST3: type-emitter=TYPE_EMITTER_ARA, type-reference=c32_ms_0_4294967294_1  # The current cycle time of the sensor
      namespaces:
        symbol props CR_Types_Namespace
    CR_FR_Interface_CyclTime_Var_ST3: type-emitter=TYPE_EMITTER_ARA, type-reference=c08_perc_0_100_1  # The current variation of the cycle time of the sensor
      namespaces:
        symbol props CR_Types_Namespace
    CR_FR_Interface_ID_ST3: type-emitter=TYPE_EMITTER_ARA, type-reference=c08_0_254_1  # Radar interface ID
      namespaces:
        symbol props CR_Types_Namespace
    CR_FR_LowDist_Dtctn_Indicator_ST3: type-emitter=TYPE_EMITTER_ARA, type-reference=c08_perc_0_100_1  # Probability of a low distance detection
      namespaces:
        symbol props CR_Types_Namespace
    CR_FR_MaxDtctn_ST3: type-emitter=TYPE_EMITTER_ARA, type-reference=c16_0_6000_1  # Maximum number of detections that could be processed by the sensor
      namespaces:
        symbol props CR_Types_Namespace
    CR_FR_Meas_Dur_ST3: type-emitter=TYPE_EMITTER_ARA, type-reference=c16_ms_0_65534_1  # Duration of the measurement time period of this frame
      namespaces:
        symbol props CR_Types_Namespace
    CR_FR_Meas_TmStmp_ST3: type-emitter=TYPE_EMITTER_ARA, type-reference=c64_ms_1_1d84467E19_1  # Timestamp of this measurment
      namespaces:
        symbol props CR_Types_Namespace
    CR_FR_Moduln_Md_ST3: type-emitter=TYPE_EMITTER_ARA, type-reference=c08_Sens_Moduln_Md_ST3  # Current modulation mode of the sensor. Each number corresponds to a specific state
      namespaces:
        symbol props CR_Types_Namespace
    CR_FR_RadVelo_LowLmt_ST3: type-emitter=TYPE_EMITTER_ARA, type-reference=c16_m_per_s_m130_0_0d01  # Lower limit of the sensor's unambigious radial velocity range
      namespaces:
        symbol props CR_Types_Namespace
    CR_FR_RadVelo_UpLmt_ST3: type-emitter=TYPE_EMITTER_ARA, type-reference=c16_m_per_s_0_130_0d01  # Upper limit of the sensor's unambigious radial velocity range
      namespaces:
        symbol props CR_Types_Namespace
    CR_FR_Radar_Header_ST3: type-emitter=TYPE_EMITTER_ARA, type-reference=REC_CR_FR_Radar_Header_ST3
      namespaces:
        symbol props CR_Types_Namespace
    CR_FR_SHI_Header_ST3: type-emitter=TYPE_EMITTER_ARA, type-reference=REC_CR_FR_SHI_Header_ST3  # Radar SHI Header
      namespaces:
        symbol props CR_Types_Namespace
    CR_FR_SPI_Header_ST3: type-emitter=TYPE_EMITTER_ARA, type-reference=REC_CR_FR_SPI_Header_ST3  # Sensor Performance Interface Header
      namespaces:
        symbol props CR_Types_Namespace
    CR_FR_SW_VerID_Major_ST3: type-emitter=TYPE_EMITTER_ARA, type-reference=c08_0_254_1  # Sensor software version ID major
      namespaces:
        symbol props CR_Types_Namespace
    CR_FR_SW_VerID_Minor_ST3: type-emitter=TYPE_EMITTER_ARA, type-reference=c08_0_254_1  # Sensor software version ID minor
      namespaces:
        symbol props CR_Types_Namespace
    CR_FR_SW_VerID_Patch_ST3: type-emitter=TYPE_EMITTER_ARA, type-reference=c08_0_254_1  # Sensor software version ID patch
      namespaces:
        symbol props CR_Types_Namespace
    CR_FR_Seg_AziAngl_Begin_ST3: type-emitter=TYPE_EMITTER_ARA, type-reference=c10_deg_m180_180_1  # Begin of segment in azimuth
      namespaces:
        symbol props CR_Types_Namespace
    CR_FR_Seg_AziAngl_End_ST3: type-emitter=TYPE_EMITTER_ARA, type-reference=c10_deg_m180_180_1  # End of segment in azimuth
      namespaces:
        symbol props CR_Types_Namespace
    CR_FR_Seg_Blockage_Stat_ST3: type-emitter=TYPE_EMITTER_ARA, type-reference=c03_SegBlock_Stat_ST3  # Segment blockage information
      namespaces:
        symbol props CR_Types_Namespace
    CR_FR_Seg_DetctnRange_Max_ST3: type-emitter=TYPE_EMITTER_ARA, type-reference=c10_m_0_400_0d5  # Maximum real detection range based on reference target
      namespaces:
        symbol props CR_Types_Namespace
    CR_FR_Seg_DetctnRange_Min_ST3: type-emitter=TYPE_EMITTER_ARA, type-reference=c10_m_0_400_0d5  # Minimum real detection range based on reference target
      namespaces:
        symbol props CR_Types_Namespace
    CR_FR_Seg_ElevAngl_Begin_ST3: type-emitter=TYPE_EMITTER_ARA, type-reference=c10_deg_m180_180_1  # Begin of segment in elevation
      namespaces:
        symbol props CR_Types_Namespace
    CR_FR_Seg_ElevAngl_End_ST3: type-emitter=TYPE_EMITTER_ARA, type-reference=c10_deg_m180_180_1  # End of segement in elevation
      namespaces:
        symbol props CR_Types_Namespace
    CR_FR_Seg_ID_ST3: type-emitter=TYPE_EMITTER_ARA, type-reference=c06_0_32_1  # Unique segment ID
      namespaces:
        symbol props CR_Types_Namespace
    CR_FR_Seg_Range_Gain_RCS_ST3: type-emitter=TYPE_EMITTER_ARA, type-reference=c10_dB_m30_30_0d1  # Reference RCS for reference target
      namespaces:
        symbol props CR_Types_Namespace
    CR_FR_Seg_Range_Gain_ST3: type-emitter=TYPE_EMITTER_ARA, type-reference=c07_perc_0_100_1  # Range gain for segment based on reference target
      namespaces:
        symbol props CR_Types_Namespace
    CR_FR_Seg_Redctn_Rsn_Prob_ST3: type-emitter=TYPE_EMITTER_ARA, type-reference=ARR_08_perc_0_100_1_8  # Segment probability for reason for blockage
      namespaces:
        symbol props CR_Types_Namespace
    CR_FR_Seg_Redctn_Rsn_ST3: type-emitter=TYPE_EMITTER_ARA, type-reference=c03_Seg_Reduction_Rsn_ST3  # Segment reason for blockage
      namespaces:
        symbol props CR_Types_Namespace
    CR_FR_Segment_ST3: type-emitter=TYPE_EMITTER_ARA, type-reference=ARR_CR_FR_Segment_ST3  # Radar Segments
      namespaces:
        symbol props CR_Types_Namespace
    CR_FR_Sens_COS_Offset_X_ST3: type-emitter=TYPE_EMITTER_ARA, type-reference=c08_m_0_2k5_0k01_NACPT_ST3  # Sensor coordinate system offset between mounting and antenna plane in x
      namespaces:
        symbol props CR_Types_Namespace
    CR_FR_Sens_COS_Offset_Y_ST3: type-emitter=TYPE_EMITTER_ARA, type-reference=c08_m_0_2k5_0k01_NACPT_ST3  # Sensor coordinate system offset between mounting and antenna plane in y
      namespaces:
        symbol props CR_Types_Namespace
    CR_FR_Sens_COS_Offset_Z_ST3: type-emitter=TYPE_EMITTER_ARA, type-reference=c08_m_0_2k5_0k01_NACPT_ST3  # Sensor coordinate system offset between mounting and antenna plane in z
      namespaces:
        symbol props CR_Types_Namespace
    CR_FR_Sens_Calib_Base_Stat_ST3: type-emitter=TYPE_EMITTER_ARA, type-reference=c02_Sens_Calib_Base_Stat_ST3  # Calibration Base State
      namespaces:
        symbol props CR_Types_Namespace
    CR_FR_Sens_Calib_Corrctn_LowLmt_Azi_ST3: type-emitter=TYPE_EMITTER_ARA, type-reference=c08_deg_m10_p10_0d1_ST3  # Lower limit of correction range in azimuth
      namespaces:
        symbol props CR_Types_Namespace
    CR_FR_Sens_Calib_Corrctn_LowLmt_Elev_ST3: type-emitter=TYPE_EMITTER_ARA, type-reference=c08_deg_m10_p10_0d1_ST3  # Lower limit of correction range in elevation
      namespaces:
        symbol props CR_Types_Namespace
    CR_FR_Sens_Calib_Corrctn_LowLmt_Roll_ST3: type-emitter=TYPE_EMITTER_ARA, type-reference=c08_deg_m10_p10_0d1_ST3  # Lower limit of correction range in elevation
      namespaces:
        symbol props CR_Types_Namespace
    CR_FR_Sens_Calib_Corrctn_Orient_Azi_ST3: type-emitter=TYPE_EMITTER_ARA, type-reference=c08_deg_m10_p10_0d1_ST3  # Current sensor mounting after correction in azimuth
      namespaces:
        symbol props CR_Types_Namespace
    CR_FR_Sens_Calib_Corrctn_Orient_Elev_ST3: type-emitter=TYPE_EMITTER_ARA, type-reference=c08_deg_m10_p10_0d1_ST3  # Current sensor mounting after correction in elevation
      namespaces:
        symbol props CR_Types_Namespace
    CR_FR_Sens_Calib_Corrctn_Orient_Roll_ST3: type-emitter=TYPE_EMITTER_ARA, type-reference=c08_deg_m10_p10_0d1_ST3  # Current sensor mounting after correction in roll
      namespaces:
        symbol props CR_Types_Namespace
    CR_FR_Sens_Calib_Corrctn_UpLmt_Azi_ST3: type-emitter=TYPE_EMITTER_ARA, type-reference=c08_deg_m10_p10_0d1_ST3  # Upper limit of correction range in azimuth
      namespaces:
        symbol props CR_Types_Namespace
    CR_FR_Sens_Calib_Corrctn_UpLmt_Elev_ST3: type-emitter=TYPE_EMITTER_ARA, type-reference=c08_deg_m10_p10_0d1_ST3  # Upper limit of correction range in elevation
      namespaces:
        symbol props CR_Types_Namespace
    CR_FR_Sens_Calib_Corrctn_UpLmt_Roll_ST3: type-emitter=TYPE_EMITTER_ARA, type-reference=c08_deg_m10_p10_0d1_ST3  # Upper limit of correction range in roll
      namespaces:
        symbol props CR_Types_Namespace
    CR_FR_Sens_Calib_Func_Stat_ST3: type-emitter=TYPE_EMITTER_ARA, type-reference=c04_Sens_Calib_Func_Stat_ST3  # Calibration Function State
      namespaces:
        symbol props CR_Types_Namespace
    CR_FR_Sens_Calib_SOC_Stat_ST3: type-emitter=TYPE_EMITTER_ARA, type-reference=c02_Sens_Calib_SOC_Stat_ST3  # Sustained Online Calibration State
      namespaces:
        symbol props CR_Types_Namespace
    CR_FR_Sens_Calib_Valid_Comp_ST3: type-emitter=TYPE_EMITTER_ARA, type-reference=c04_0_15_1_SNA_na  # Number of valid sensor calibration components
      namespaces:
        symbol props CR_Types_Namespace
    CR_FR_Sens_Defect_Dtct_ST3: type-emitter=TYPE_EMITTER_ARA, type-reference=c02_Sens_Defect_Dtct_ST3  # Defect state of sensor
      namespaces:
        symbol props CR_Types_Namespace
    CR_FR_Sens_Defect_Rsn_ST3: type-emitter=TYPE_EMITTER_ARA, type-reference=c03_Sens_Defect_Rsn_ST3  # Reasons of sensor defect
      namespaces:
        symbol props CR_Types_Namespace
    CR_FR_Sens_Diag_Md_ST3: type-emitter=TYPE_EMITTER_ARA, type-reference=c02_Diag_Mode_ST3  # State of sensor diagnostic interface
      namespaces:
        symbol props CR_Types_Namespace
    CR_FR_Sens_Extern_Disturbnc_ST3: type-emitter=TYPE_EMITTER_ARA, type-reference=c02_Sens_Disturbnc_Stat_ST3  # Status of disturbance by electromagentic phenomenon (interference)
      namespaces:
        symbol props CR_Types_Namespace
    CR_FR_Sens_GTS_Offset_ST3: type-emitter=TYPE_EMITTER_ARA, type-reference=c32_ns_0_4294967295_1_noSNA  # Offset time of GTS
      namespaces:
        symbol props CR_Types_Namespace
    CR_FR_Sens_Oprtn_Md_ST3: type-emitter=TYPE_EMITTER_ARA, type-reference=c02_Sens_Oprtn_Md_ST3  # Measuring state of sensor
      namespaces:
        symbol props CR_Types_Namespace
    CR_FR_Sens_Oprtn_Stat_ST3: type-emitter=TYPE_EMITTER_ARA, type-reference=c02_Sens_Oprtn_Stat_ST3  # Overall state of sensor health
      namespaces:
        symbol props CR_Types_Namespace
    CR_FR_Sens_Orient_Azi_ST3: type-emitter=TYPE_EMITTER_ARA, type-reference=c08_deg_m10_p10_0d1_ST3  # Sensor mounting orientation in azimuth
      namespaces:
        symbol props CR_Types_Namespace
    CR_FR_Sens_Orient_Elev_ST3: type-emitter=TYPE_EMITTER_ARA, type-reference=c08_deg_m10_p10_0d1_ST3  # Sensor mounting orientation in elevation
      namespaces:
        symbol props CR_Types_Namespace
    CR_FR_Sens_Orient_Err_Azi_ST3: type-emitter=TYPE_EMITTER_ARA, type-reference=c08_deg_m10_p10_0d1_ST3  # Sensor mounting orientation error in azimuth
      namespaces:
        symbol props CR_Types_Namespace
    CR_FR_Sens_Orient_Err_Elev_ST3: type-emitter=TYPE_EMITTER_ARA, type-reference=c08_deg_m10_p10_0d1_ST3  # Sensor mounting orientation error in elevation
      namespaces:
        symbol props CR_Types_Namespace
    CR_FR_Sens_Orient_Err_Roll_ST3: type-emitter=TYPE_EMITTER_ARA, type-reference=c08_deg_m10_p10_0d1_ST3  # Sensor mounting orientation error in roll
      namespaces:
        symbol props CR_Types_Namespace
    CR_FR_Sens_Orient_Roll_ST3: type-emitter=TYPE_EMITTER_ARA, type-reference=c08_deg_m10_p10_0d1_ST3  # Sensor mounting orientation in roll
      namespaces:
        symbol props CR_Types_Namespace
    CR_FR_Sens_Origin_Pos_Err_X_ST3: type-emitter=TYPE_EMITTER_ARA, type-reference=c08_m_0_2k5_0k01_NACPT_ST3  # Sensor mounting position error in x
      namespaces:
        symbol props CR_Types_Namespace
    CR_FR_Sens_Origin_Pos_Err_Y_ST3: type-emitter=TYPE_EMITTER_ARA, type-reference=c08_m_0_2k5_0k01_NACPT_ST3  # Sensor mounting position error in y
      namespaces:
        symbol props CR_Types_Namespace
    CR_FR_Sens_Origin_Pos_Err_Z_ST3: type-emitter=TYPE_EMITTER_ARA, type-reference=c08_m_0_2k5_0k01_NACPT_ST3  # Sensor mounting position error in z
      namespaces:
        symbol props CR_Types_Namespace
    CR_FR_Sens_Origin_Pos_X_ST3: type-emitter=TYPE_EMITTER_ARA, type-reference=c08_m_0_2k5_0k01_NACPT_ST3  # Sensor mounting position in x
      namespaces:
        symbol props CR_Types_Namespace
    CR_FR_Sens_Origin_Pos_Y_ST3: type-emitter=TYPE_EMITTER_ARA, type-reference=c08_m_0_2k5_0k01_NACPT_ST3  # Sensor mounting position in y
      namespaces:
        symbol props CR_Types_Namespace
    CR_FR_Sens_Origin_Pos_Z_ST3: type-emitter=TYPE_EMITTER_ARA, type-reference=c08_m_0_2k5_0k01_NACPT_ST3  # Sensor mounting position in z
      namespaces:
        symbol props CR_Types_Namespace
    CR_FR_Sens_Radom_Heat_Stat_ST3: type-emitter=TYPE_EMITTER_ARA, type-reference=c02_Sens_Radom_Heat_Stat_ST3  # Status of radom heating driver
      namespaces:
        symbol props CR_Types_Namespace
    CR_FR_Sens_Supp_Vtg_Stat_ST3: type-emitter=TYPE_EMITTER_ARA, type-reference=c02_Sens_SuppVtg_Stat_ST3  # State of supply voltage
      namespaces:
        symbol props CR_Types_Namespace
    CR_FR_Sens_Temp_Stat_ST3: type-emitter=TYPE_EMITTER_ARA, type-reference=c02_Sens_Temp_Stat_ST3  # State of internal sensor ECU temperature
      namespaces:
        symbol props CR_Types_Namespace
    CR_FR_Sens_TmSync_Stat_ST3: type-emitter=TYPE_EMITTER_ARA, type-reference=c02_Sens_TimeSync_Stat_ST3  # Status of GTS time sync
      namespaces:
        symbol props CR_Types_Namespace
    CR_FR_Sens_Total_Seg_Azi_ST3: type-emitter=TYPE_EMITTER_ARA, type-reference=c06_0_32_1  # Total (valid + invalid) number of segments in azimuth
      namespaces:
        symbol props CR_Types_Namespace
    CR_FR_Sens_Total_Seg_Elev_ST3: type-emitter=TYPE_EMITTER_ARA, type-reference=c06_0_32_1  # Total (valid + invalid) number of segments in elevation
      namespaces:
        symbol props CR_Types_Namespace
    CR_FR_Sens_Tx_PwrRedctn_Stat_ST3: type-emitter=TYPE_EMITTER_ARA, type-reference=c02_Sens_TxPwrRedctn_Stat_ST3  # Status of RF transmission
      namespaces:
        symbol props CR_Types_Namespace
    CR_FR_Sens_Valid_InputSignals_Curr_ST3: type-emitter=TYPE_EMITTER_ARA, type-reference=c08_UInt_SNA_na  # Number of currently valid input signals
      namespaces:
        symbol props CR_Types_Namespace
    CR_FR_Sens_Valid_InputSignals_Trgt_ST3: type-emitter=TYPE_EMITTER_ARA, type-reference=c08_UInt_SNA_na  # Number of target valid input signals
      namespaces:
        symbol props CR_Types_Namespace
    CR_FR_Sens_Valid_Seg_Azi_ST3: type-emitter=TYPE_EMITTER_ARA, type-reference=c06_0_32_1  # Valid number of segments in azimuth
      namespaces:
        symbol props CR_Types_Namespace
    CR_FR_Sens_Valid_Seg_Elev_ST3: type-emitter=TYPE_EMITTER_ARA, type-reference=c06_0_32_1  # Valid number of segments in elevation
      namespaces:
        symbol props CR_Types_Namespace
    CR_FR_SensorID_ST3: type-emitter=TYPE_EMITTER_ARA, type-reference=c08_0_254_1  # Sensor ID
      namespaces:
        symbol props CR_Types_Namespace
    CR_FR_ValidDtctn_ST3: type-emitter=TYPE_EMITTER_ARA, type-reference=c16_0_6000_1  # Number of valid detections in this measurement
      namespaces:
        symbol props CR_Types_Namespace
    CR_RL_AziAngl_LowLmt_ST3: type-emitter=TYPE_EMITTER_ARA, type-reference=c16_rad_m157_0_0d001  # Upper limit of the sensor's unambigious azimuth domain
      namespaces:
        symbol props CR_Types_Namespace
    CR_RL_AziAngl_UpLmt_ST3: type-emitter=TYPE_EMITTER_ARA, type-reference=c16_rad_0_1d57_0d001  # Lower limit of the sensor's unambigious azimuth domain
      namespaces:
        symbol props CR_Types_Namespace
    CR_RL_Cycl_Count_ST3: type-emitter=TYPE_EMITTER_ARA, type-reference=c64_0_0_1d84467E19_1_SNA  # Consecutive cycle count
      namespaces:
        symbol props CR_Types_Namespace
    CR_RL_Data_Qual_ST3: type-emitter=TYPE_EMITTER_ARA, type-reference=c08_Sens_Data_Qual_ST3  # Status ID representing the current quality level of the sensor
      namespaces:
        symbol props CR_Types_Namespace
    CR_RL_Detection_ST3: type-emitter=TYPE_EMITTER_ARA, type-reference=ARR_CR_RL_Detection_ST3
      namespaces:
        symbol props CR_Types_Namespace
    CR_RL_Dist_RadVelo_Cov_ST3: type-emitter=TYPE_EMITTER_ARA, type-reference=c08_m_sq_p_s_m0d01_p0d01_0d00008  # Covariance of the distance and radial velocity dimension
      namespaces:
        symbol props CR_Types_Namespace
    CR_RL_Dist_Range__ST3: type-emitter=TYPE_EMITTER_ARA, type-reference=c16_m_0_500_0d1  # Upper limit of the sensor's range ambiguity domain
      namespaces:
        symbol props CR_Types_Namespace
    CR_RL_Dtct_SNR_Err_ST3: type-emitter=TYPE_EMITTER_ARA, type-reference=c08_dB_0_5_0d02
      namespaces:
        symbol props CR_Types_Namespace
    CR_RL_Dtctn_Ambgt_ID_ST3: type-emitter=TYPE_EMITTER_ARA, type-reference=c16_0_3000_1
      namespaces:
        symbol props CR_Types_Namespace
    CR_RL_Dtctn_Ambgt_Probb_ST3: type-emitter=TYPE_EMITTER_ARA, type-reference=c08_perc_0_100_1
      namespaces:
        symbol props CR_Types_Namespace
    CR_RL_Dtctn_Azi_Qual_ST3: type-emitter=TYPE_EMITTER_ARA, type-reference=c08_0_100_1
      namespaces:
        symbol props CR_Types_Namespace
    CR_RL_Dtctn_Azi_ST3: type-emitter=TYPE_EMITTER_ARA, type-reference=c16_rad_m1d571_1d57_0d0001745
      namespaces:
        symbol props CR_Types_Namespace
    CR_RL_Dtctn_Azi_StdDev_ST3: type-emitter=TYPE_EMITTER_ARA, type-reference=c08_rad_0_0d044323_0d0001745
      namespaces:
        symbol props CR_Types_Namespace
    CR_RL_Dtctn_Dist_Qual_ST3: type-emitter=TYPE_EMITTER_ARA, type-reference=c08_0_100_1
      namespaces:
        symbol props CR_Types_Namespace
    CR_RL_Dtctn_Dist_ST3: type-emitter=TYPE_EMITTER_ARA, type-reference=c32_m_0_500_0d001
      namespaces:
        symbol props CR_Types_Namespace
    CR_RL_Dtctn_Dist_StdDev_ST3: type-emitter=TYPE_EMITTER_ARA, type-reference=c08_m_0_1d02_0d004_no_SNA
      namespaces:
        symbol props CR_Types_Namespace
    CR_RL_Dtctn_Elev_Qual_ST3: type-emitter=TYPE_EMITTER_ARA, type-reference=c08_0_100_1
      namespaces:
        symbol props CR_Types_Namespace
    CR_RL_Dtctn_Elev_ST3: type-emitter=TYPE_EMITTER_ARA, type-reference=c16_rad_m1d571_1d57_0d0001745
      namespaces:
        symbol props CR_Types_Namespace
    CR_RL_Dtctn_Elev_StdDev_ST3: type-emitter=TYPE_EMITTER_ARA, type-reference=c08_rad_0_0d0886714_0d0001745
      namespaces:
        symbol props CR_Types_Namespace
    CR_RL_Dtctn_Existence_Prob_ST3: type-emitter=TYPE_EMITTER_ARA, type-reference=c08_perc_0_100_1
      namespaces:
        symbol props CR_Types_Namespace
    CR_RL_Dtctn_FreeSp_Probb_ST3: type-emitter=TYPE_EMITTER_ARA, type-reference=c08_perc_0_100_1
      namespaces:
        symbol props CR_Types_Namespace
    CR_RL_Dtctn_ID_Part1_ST3: type-emitter=TYPE_EMITTER_ARA, type-reference=c64_0_0_1d84467E19_1_SNA
      namespaces:
        symbol props CR_Types_Namespace
    CR_RL_Dtctn_ID_Part2_ST3: type-emitter=TYPE_EMITTER_ARA, type-reference=c64_0_0_1d84467E19_1_SNA
      namespaces:
        symbol props CR_Types_Namespace
    CR_RL_Dtctn_MaskAnglSect_Azi_ST3: type-emitter=TYPE_EMITTER_ARA, type-reference=c08_rad_0_3d1416_0d01232_no_SNA
      namespaces:
        symbol props CR_Types_Namespace
    CR_RL_Dtctn_MaskAnglSect_Elev_ST3: type-emitter=TYPE_EMITTER_ARA, type-reference=c08_rad_0_3d1416_0d01232_no_SNA
      namespaces:
        symbol props CR_Types_Namespace
    CR_RL_Dtctn_Meas_Model_ST3: type-emitter=TYPE_EMITTER_ARA, type-reference=c08_Sens_MeasModel_ST3
      namespaces:
        symbol props CR_Types_Namespace
    CR_RL_Dtctn_Micro_Doppler_Val_ST3: type-emitter=TYPE_EMITTER_ARA, type-reference=c08_0_to_3_1_SNA_255
      namespaces:
        symbol props CR_Types_Namespace
    CR_RL_Dtctn_MultiTrgt_Probb_ST3: type-emitter=TYPE_EMITTER_ARA, type-reference=c08_perc_0_100_1
      namespaces:
        symbol props CR_Types_Namespace
    CR_RL_Dtctn_PeakDtct_Thrsld_ST3: type-emitter=TYPE_EMITTER_ARA, type-reference=c08_dB_0_20_0d1
      namespaces:
        symbol props CR_Types_Namespace
    CR_RL_Dtctn_RCS_Err_ST3: type-emitter=TYPE_EMITTER_ARA, type-reference=c08_dBsm_0_2d54_0d01
      namespaces:
        symbol props CR_Types_Namespace
    CR_RL_Dtctn_RCS_ST3: type-emitter=TYPE_EMITTER_ARA, type-reference=c16_dBsm_m100_p100_0d0035
      namespaces:
        symbol props CR_Types_Namespace
    CR_RL_Dtctn_RadRelVelo_Ambgt_Resolv_ST3: type-emitter=TYPE_EMITTER_ARA, type-reference=c02_Fls_Tru
      namespaces:
        symbol props CR_Types_Namespace
    CR_RL_Dtctn_RadRelVelo_ST3: type-emitter=TYPE_EMITTER_ARA, type-reference=c32_m_per_s_m200_100_0d001
      namespaces:
        symbol props CR_Types_Namespace
    CR_RL_Dtctn_RadRelVelo_StdDev_ST3: type-emitter=TYPE_EMITTER_ARA, type-reference=c08_m_p_s_0_0d663_0d0026_No_SNA
      namespaces:
        symbol props CR_Types_Namespace
    CR_RL_Dtctn_RadVelo_Qual_ST3: type-emitter=TYPE_EMITTER_ARA, type-reference=c08_0_100_1
      namespaces:
        symbol props CR_Types_Namespace
    CR_RL_Dtctn_RxSig_Strength_ST3: type-emitter=TYPE_EMITTER_ARA, type-reference=c08_dB_m254_0_1
      namespaces:
        symbol props CR_Types_Namespace
    CR_RL_Dtctn_SNR_ST3: type-emitter=TYPE_EMITTER_ARA, type-reference=c08_dB_0_50_0d2
      namespaces:
        symbol props CR_Types_Namespace
    CR_RL_Dtctn_Stat_ST3: type-emitter=TYPE_EMITTER_ARA, type-reference=c08_Sens_Dtctn_Stat_ST3  # Current status of the sensor. Each number corresponds to a specific state
      namespaces:
        symbol props CR_Types_Namespace
    CR_RL_Dtctn_StaticObj_Stat_ST3: type-emitter=TYPE_EMITTER_ARA, type-reference=c02_Fls_Tru
      namespaces:
        symbol props CR_Types_Namespace
    CR_RL_ElevAngl_LowLmt_ST3: type-emitter=TYPE_EMITTER_ARA, type-reference=c8_rad_m1d404_0_0d006  # Upper limit of the sensor's unambigious elevation domain
      namespaces:
        symbol props CR_Types_Namespace
    CR_RL_ElevAngl_UpLmt_ST3: type-emitter=TYPE_EMITTER_ARA, type-reference=c8_rad_0_1d404_0d006  # Lower limit of the sensor's unambigious elevation domain
      namespaces:
        symbol props CR_Types_Namespace
    CR_RL_Gen_Header_ST3: type-emitter=TYPE_EMITTER_ARA, type-reference=REC_CR_RL_Gen_Header_ST3
      namespaces:
        symbol props CR_Types_Namespace
    CR_RL_Interface_CyclTime_ST3: type-emitter=TYPE_EMITTER_ARA, type-reference=c32_ms_0_4294967294_1  # The current cycle time of the sensor
      namespaces:
        symbol props CR_Types_Namespace
    CR_RL_Interface_CyclTime_Var_ST3: type-emitter=TYPE_EMITTER_ARA, type-reference=c08_perc_0_100_1  # The current variation of the cycle time of the sensor
      namespaces:
        symbol props CR_Types_Namespace
    CR_RL_Interface_ID_ST3: type-emitter=TYPE_EMITTER_ARA, type-reference=c08_0_254_1  # Radar interface ID
      namespaces:
        symbol props CR_Types_Namespace
    CR_RL_LowDist_Dtctn_Indicator_ST3: type-emitter=TYPE_EMITTER_ARA, type-reference=c08_perc_0_100_1  # Probability of a low distance detection
      namespaces:
        symbol props CR_Types_Namespace
    CR_RL_MaxDtctn_ST3: type-emitter=TYPE_EMITTER_ARA, type-reference=c16_0_6000_1  # Maximum number of detections that could be processed by the sensor
      namespaces:
        symbol props CR_Types_Namespace
    CR_RL_Meas_Dur_ST3: type-emitter=TYPE_EMITTER_ARA, type-reference=c16_ms_0_65534_1  # Duration of the measurement time period of this frame
      namespaces:
        symbol props CR_Types_Namespace
    CR_RL_Meas_TmStmp_ST3: type-emitter=TYPE_EMITTER_ARA, type-reference=c64_ms_1_1d84467E19_1  # Timestamp of this measurment
      namespaces:
        symbol props CR_Types_Namespace
    CR_RL_Moduln_Md_ST3: type-emitter=TYPE_EMITTER_ARA, type-reference=c08_Sens_Moduln_Md_ST3  # Current modulation mode of the sensor. Each number corresponds to a specific state
      namespaces:
        symbol props CR_Types_Namespace
    CR_RL_RadVelo_LowLmt_ST3: type-emitter=TYPE_EMITTER_ARA, type-reference=c16_m_per_s_m130_0_0d01  # Lower limit of the sensor's unambigious radial velocity range
      namespaces:
        symbol props CR_Types_Namespace
    CR_RL_RadVelo_UpLmt_ST3: type-emitter=TYPE_EMITTER_ARA, type-reference=c16_m_per_s_0_130_0d01  # Upper limit of the sensor's unambigious radial velocity range
      namespaces:
        symbol props CR_Types_Namespace
    CR_RL_Radar_Header_ST3: type-emitter=TYPE_EMITTER_ARA, type-reference=REC_CR_RL_Radar_Header_ST3
      namespaces:
        symbol props CR_Types_Namespace
    CR_RL_SHI_Header_ST3: type-emitter=TYPE_EMITTER_ARA, type-reference=REC_CR_RL_SHI_Header_ST3  # Radar SHI Header
      namespaces:
        symbol props CR_Types_Namespace
    CR_RL_SPI_Header_ST3: type-emitter=TYPE_EMITTER_ARA, type-reference=REC_CR_RL_SPI_Header_ST3  # Sensor Performance Interface Header
      namespaces:
        symbol props CR_Types_Namespace
    CR_RL_SW_VerID_Major_ST3: type-emitter=TYPE_EMITTER_ARA, type-reference=c08_0_254_1  # Sensor software version ID major
      namespaces:
        symbol props CR_Types_Namespace
    CR_RL_SW_VerID_Minor_ST3: type-emitter=TYPE_EMITTER_ARA, type-reference=c08_0_254_1  # Sensor software version ID minor
      namespaces:
        symbol props CR_Types_Namespace
    CR_RL_SW_VerID_Patch_ST3: type-emitter=TYPE_EMITTER_ARA, type-reference=c08_0_254_1  # Sensor software version ID patch
      namespaces:
        symbol props CR_Types_Namespace
    CR_RL_Seg_AziAngl_Begin_ST3: type-emitter=TYPE_EMITTER_ARA, type-reference=c10_deg_m180_180_1  # Begin of segment in azimuth
      namespaces:
        symbol props CR_Types_Namespace
    CR_RL_Seg_AziAngl_End_ST3: type-emitter=TYPE_EMITTER_ARA, type-reference=c10_deg_m180_180_1  # End of segment in azimuth
      namespaces:
        symbol props CR_Types_Namespace
    CR_RL_Seg_Blockage_Stat_ST3: type-emitter=TYPE_EMITTER_ARA, type-reference=c03_SegBlock_Stat_ST3  # Segment blockage information
      namespaces:
        symbol props CR_Types_Namespace
    CR_RL_Seg_DetctnRange_Max_ST3: type-emitter=TYPE_EMITTER_ARA, type-reference=c10_m_0_400_0d5  # Maximum real detection range based on reference target
      namespaces:
        symbol props CR_Types_Namespace
    CR_RL_Seg_DetctnRange_Min_ST3: type-emitter=TYPE_EMITTER_ARA, type-reference=c10_m_0_400_0d5  # Minimum real detection range based on reference target
      namespaces:
        symbol props CR_Types_Namespace
    CR_RL_Seg_ElevAngl_Begin_ST3: type-emitter=TYPE_EMITTER_ARA, type-reference=c10_deg_m180_180_1  # Begin of segment in elevation
      namespaces:
        symbol props CR_Types_Namespace
    CR_RL_Seg_ElevAngl_End_ST3: type-emitter=TYPE_EMITTER_ARA, type-reference=c10_deg_m180_180_1  # End of segement in elevation
      namespaces:
        symbol props CR_Types_Namespace
    CR_RL_Seg_ID_ST3: type-emitter=TYPE_EMITTER_ARA, type-reference=c06_0_32_1  # Unique segment ID
      namespaces:
        symbol props CR_Types_Namespace
    CR_RL_Seg_Range_Gain_RCS_ST3: type-emitter=TYPE_EMITTER_ARA, type-reference=c10_dB_m30_30_0d1  # Reference RCS for reference target
      namespaces:
        symbol props CR_Types_Namespace
    CR_RL_Seg_Range_Gain_ST3: type-emitter=TYPE_EMITTER_ARA, type-reference=c07_perc_0_100_1  # Range gain for segment based on reference target
      namespaces:
        symbol props CR_Types_Namespace
    CR_RL_Seg_Redctn_Rsn_Prob_ST3: type-emitter=TYPE_EMITTER_ARA, type-reference=ARR_08_perc_0_100_1_8  # Segment probability for reason for blockage
      namespaces:
        symbol props CR_Types_Namespace
    CR_RL_Seg_Redctn_Rsn_ST3: type-emitter=TYPE_EMITTER_ARA, type-reference=c03_Seg_Reduction_Rsn_ST3  # Segment reason for blockage
      namespaces:
        symbol props CR_Types_Namespace
    CR_RL_Segment_ST3: type-emitter=TYPE_EMITTER_ARA, type-reference=ARR_CR_RL_Segment_ST3  # Radar Segments
      namespaces:
        symbol props CR_Types_Namespace
    CR_RL_Sens_COS_Offset_X_ST3: type-emitter=TYPE_EMITTER_ARA, type-reference=c08_m_0_2k5_0k01_NACPT_ST3  # Sensor coordinate system offset between mounting and antenna plane in x
      namespaces:
        symbol props CR_Types_Namespace
    CR_RL_Sens_COS_Offset_Y_ST3: type-emitter=TYPE_EMITTER_ARA, type-reference=c08_m_0_2k5_0k01_NACPT_ST3  # Sensor coordinate system offset between mounting and antenna plane in y
      namespaces:
        symbol props CR_Types_Namespace
    CR_RL_Sens_COS_Offset_Z_ST3: type-emitter=TYPE_EMITTER_ARA, type-reference=c08_m_0_2k5_0k01_NACPT_ST3  # Sensor coordinate system offset between mounting and antenna plane in z
      namespaces:
        symbol props CR_Types_Namespace
    CR_RL_Sens_Calib_Base_Stat_ST3: type-emitter=TYPE_EMITTER_ARA, type-reference=c02_Sens_Calib_Base_Stat_ST3  # Calibration Base State
      namespaces:
        symbol props CR_Types_Namespace
    CR_RL_Sens_Calib_Corrctn_LowLmt_Azi_ST3: type-emitter=TYPE_EMITTER_ARA, type-reference=c08_deg_m10_p10_0d1_ST3  # Lower limit of correction range in azimuth
      namespaces:
        symbol props CR_Types_Namespace
    CR_RL_Sens_Calib_Corrctn_LowLmt_Elev_ST3: type-emitter=TYPE_EMITTER_ARA, type-reference=c08_deg_m10_p10_0d1_ST3  # Lower limit of correction range in elevation
      namespaces:
        symbol props CR_Types_Namespace
    CR_RL_Sens_Calib_Corrctn_LowLmt_Roll_ST3: type-emitter=TYPE_EMITTER_ARA, type-reference=c08_deg_m10_p10_0d1_ST3  # Lower limit of correction range in elevation
      namespaces:
        symbol props CR_Types_Namespace
    CR_RL_Sens_Calib_Corrctn_Orient_Azi_ST3: type-emitter=TYPE_EMITTER_ARA, type-reference=c08_deg_m10_p10_0d1_ST3  # Current sensor mounting after correction in azimuth
      namespaces:
        symbol props CR_Types_Namespace
    CR_RL_Sens_Calib_Corrctn_Orient_Elev_ST3: type-emitter=TYPE_EMITTER_ARA, type-reference=c08_deg_m10_p10_0d1_ST3  # Current sensor mounting after correction in elevation
      namespaces:
        symbol props CR_Types_Namespace
    CR_RL_Sens_Calib_Corrctn_Orient_Roll_ST3: type-emitter=TYPE_EMITTER_ARA, type-reference=c08_deg_m10_p10_0d1_ST3  # Current sensor mounting after correction in roll
      namespaces:
        symbol props CR_Types_Namespace
    CR_RL_Sens_Calib_Corrctn_UpLmt_Azi_ST3: type-emitter=TYPE_EMITTER_ARA, type-reference=c08_deg_m10_p10_0d1_ST3  # Upper limit of correction range in azimuth
      namespaces:
        symbol props CR_Types_Namespace
    CR_RL_Sens_Calib_Corrctn_UpLmt_Elev_ST3: type-emitter=TYPE_EMITTER_ARA, type-reference=c08_deg_m10_p10_0d1_ST3  # Upper limit of correction range in elevation
      namespaces:
        symbol props CR_Types_Namespace
    CR_RL_Sens_Calib_Corrctn_UpLmt_Roll_ST3: type-emitter=TYPE_EMITTER_ARA, type-reference=c08_deg_m10_p10_0d1_ST3  # Upper limit of correction range in roll
      namespaces:
        symbol props CR_Types_Namespace
    CR_RL_Sens_Calib_Func_Stat_ST3: type-emitter=TYPE_EMITTER_ARA, type-reference=c04_Sens_Calib_Func_Stat_ST3  # Calibration Function State
      namespaces:
        symbol props CR_Types_Namespace
    CR_RL_Sens_Calib_SOC_Stat_ST3: type-emitter=TYPE_EMITTER_ARA, type-reference=c02_Sens_Calib_SOC_Stat_ST3  # Sustained Online Calibration State
      namespaces:
        symbol props CR_Types_Namespace
    CR_RL_Sens_Calib_Valid_Comp_ST3: type-emitter=TYPE_EMITTER_ARA, type-reference=c04_0_15_1_SNA_na  # Number of valid sensor calibration components
      namespaces:
        symbol props CR_Types_Namespace
    CR_RL_Sens_Defect_Dtct_ST3: type-emitter=TYPE_EMITTER_ARA, type-reference=c02_Sens_Defect_Dtct_ST3  # Defect state of sensor
      namespaces:
        symbol props CR_Types_Namespace
    CR_RL_Sens_Defect_Rsn_ST3: type-emitter=TYPE_EMITTER_ARA, type-reference=c03_Sens_Defect_Rsn_ST3  # Reasons of sensor defect
      namespaces:
        symbol props CR_Types_Namespace
    CR_RL_Sens_Diag_Md_ST3: type-emitter=TYPE_EMITTER_ARA, type-reference=c02_Diag_Mode_ST3  # State of sensor diagnostic interface
      namespaces:
        symbol props CR_Types_Namespace
    CR_RL_Sens_Extern_Disturbnc_ST3: type-emitter=TYPE_EMITTER_ARA, type-reference=c02_Sens_Disturbnc_Stat_ST3  # Status of disturbance by electromagentic phenomenon (interference)
      namespaces:
        symbol props CR_Types_Namespace
    CR_RL_Sens_GTS_Offset_ST3: type-emitter=TYPE_EMITTER_ARA, type-reference=c32_ns_0_4294967295_1_noSNA  # Offset time of GTS
      namespaces:
        symbol props CR_Types_Namespace
    CR_RL_Sens_Oprtn_Md_ST3: type-emitter=TYPE_EMITTER_ARA, type-reference=c02_Sens_Oprtn_Md_ST3  # Measuring state of sensor
      namespaces:
        symbol props CR_Types_Namespace
    CR_RL_Sens_Oprtn_Stat_ST3: type-emitter=TYPE_EMITTER_ARA, type-reference=c02_Sens_Oprtn_Stat_ST3  # Overall state of sensor health
      namespaces:
        symbol props CR_Types_Namespace
    CR_RL_Sens_Orient_Azi_ST3: type-emitter=TYPE_EMITTER_ARA, type-reference=c08_deg_m10_p10_0d1_ST3  # Sensor mounting orientation in azimuth
      namespaces:
        symbol props CR_Types_Namespace
    CR_RL_Sens_Orient_Elev_ST3: type-emitter=TYPE_EMITTER_ARA, type-reference=c08_deg_m10_p10_0d1_ST3  # Sensor mounting orientation in elevation
      namespaces:
        symbol props CR_Types_Namespace
    CR_RL_Sens_Orient_Err_Azi_ST3: type-emitter=TYPE_EMITTER_ARA, type-reference=c08_deg_m10_p10_0d1_ST3  # Sensor mounting orientation error in azimuth
      namespaces:
        symbol props CR_Types_Namespace
    CR_RL_Sens_Orient_Err_Elev_ST3: type-emitter=TYPE_EMITTER_ARA, type-reference=c08_deg_m10_p10_0d1_ST3  # Sensor mounting orientation error in elevation
      namespaces:
        symbol props CR_Types_Namespace
    CR_RL_Sens_Orient_Err_Roll_ST3: type-emitter=TYPE_EMITTER_ARA, type-reference=c08_deg_m10_p10_0d1_ST3  # Sensor mounting orientation error in roll
      namespaces:
        symbol props CR_Types_Namespace
    CR_RL_Sens_Orient_Roll_ST3: type-emitter=TYPE_EMITTER_ARA, type-reference=c08_deg_m10_p10_0d1_ST3  # Sensor mounting orientation in roll
      namespaces:
        symbol props CR_Types_Namespace
    CR_RL_Sens_Origin_Pos_Err_X_ST3: type-emitter=TYPE_EMITTER_ARA, type-reference=c08_m_0_2k5_0k01_NACPT_ST3  # Sensor mounting position error in x
      namespaces:
        symbol props CR_Types_Namespace
    CR_RL_Sens_Origin_Pos_Err_Y_ST3: type-emitter=TYPE_EMITTER_ARA, type-reference=c08_m_0_2k5_0k01_NACPT_ST3  # Sensor mounting position error in y
      namespaces:
        symbol props CR_Types_Namespace
    CR_RL_Sens_Origin_Pos_Err_Z_ST3: type-emitter=TYPE_EMITTER_ARA, type-reference=c08_m_0_2k5_0k01_NACPT_ST3  # Sensor mounting position error in z
      namespaces:
        symbol props CR_Types_Namespace
    CR_RL_Sens_Origin_Pos_X_ST3: type-emitter=TYPE_EMITTER_ARA, type-reference=c08_m_0_2k5_0k01_NACPT_ST3  # Sensor mounting position in x
      namespaces:
        symbol props CR_Types_Namespace
    CR_RL_Sens_Origin_Pos_Y_ST3: type-emitter=TYPE_EMITTER_ARA, type-reference=c08_m_0_2k5_0k01_NACPT_ST3  # Sensor mounting position in y
      namespaces:
        symbol props CR_Types_Namespace
    CR_RL_Sens_Origin_Pos_Z_ST3: type-emitter=TYPE_EMITTER_ARA, type-reference=c08_m_0_2k5_0k01_NACPT_ST3  # Sensor mounting position in z
      namespaces:
        symbol props CR_Types_Namespace
    CR_RL_Sens_Radom_Heat_Stat_ST3: type-emitter=TYPE_EMITTER_ARA, type-reference=c02_Sens_Radom_Heat_Stat_ST3  # Status of radom heating driver
      namespaces:
        symbol props CR_Types_Namespace
    CR_RL_Sens_Supp_Vtg_Stat_ST3: type-emitter=TYPE_EMITTER_ARA, type-reference=c02_Sens_SuppVtg_Stat_ST3  # State of supply voltage
      namespaces:
        symbol props CR_Types_Namespace
    CR_RL_Sens_Temp_Stat_ST3: type-emitter=TYPE_EMITTER_ARA, type-reference=c02_Sens_Temp_Stat_ST3  # State of internal sensor ECU temperature
      namespaces:
        symbol props CR_Types_Namespace
    CR_RL_Sens_TmSync_Stat_ST3: type-emitter=TYPE_EMITTER_ARA, type-reference=c02_Sens_TimeSync_Stat_ST3  # Status of GTS time sync
      namespaces:
        symbol props CR_Types_Namespace
    CR_RL_Sens_Total_Seg_Azi_ST3: type-emitter=TYPE_EMITTER_ARA, type-reference=c06_0_32_1  # Total (valid + invalid) number of segments in azimuth
      namespaces:
        symbol props CR_Types_Namespace
    CR_RL_Sens_Total_Seg_Elev_ST3: type-emitter=TYPE_EMITTER_ARA, type-reference=c06_0_32_1  # Total (valid + invalid) number of segments in elevation
      namespaces:
        symbol props CR_Types_Namespace
    CR_RL_Sens_Tx_PwrRedctn_Stat_ST3: type-emitter=TYPE_EMITTER_ARA, type-reference=c02_Sens_TxPwrRedctn_Stat_ST3  # Status of RF transmission
      namespaces:
        symbol props CR_Types_Namespace
    CR_RL_Sens_Valid_InputSignals_Curr_ST3: type-emitter=TYPE_EMITTER_ARA, type-reference=c08_UInt_SNA_na  # Number of currently valid input signals
      namespaces:
        symbol props CR_Types_Namespace
    CR_RL_Sens_Valid_InputSignals_Trgt_ST3: type-emitter=TYPE_EMITTER_ARA, type-reference=c08_UInt_SNA_na  # Number of target valid input signals
      namespaces:
        symbol props CR_Types_Namespace
    CR_RL_Sens_Valid_Seg_Azi_ST3: type-emitter=TYPE_EMITTER_ARA, type-reference=c06_0_32_1  # Valid number of segments in azimuth
      namespaces:
        symbol props CR_Types_Namespace
    CR_RL_Sens_Valid_Seg_Elev_ST3: type-emitter=TYPE_EMITTER_ARA, type-reference=c06_0_32_1  # Valid number of segments in elevation
      namespaces:
        symbol props CR_Types_Namespace
    CR_RL_SensorID_ST3: type-emitter=TYPE_EMITTER_ARA, type-reference=c08_0_254_1  # Sensor ID
      namespaces:
        symbol props CR_Types_Namespace
    CR_RL_ValidDtctn_ST3: type-emitter=TYPE_EMITTER_ARA, type-reference=c16_0_6000_1  # Number of valid detections in this measurement
      namespaces:
        symbol props CR_Types_Namespace
    CR_RR_AziAngl_LowLmt_ST3: type-emitter=TYPE_EMITTER_ARA, type-reference=c16_rad_m157_0_0d001  # Upper limit of the sensor's unambigious azimuth domain
      namespaces:
        symbol props CR_Types_Namespace
    CR_RR_AziAngl_UpLmt_ST3: type-emitter=TYPE_EMITTER_ARA, type-reference=c16_rad_0_1d57_0d001  # Lower limit of the sensor's unambigious azimuth domain
      namespaces:
        symbol props CR_Types_Namespace
    CR_RR_Cycl_Count_ST3: type-emitter=TYPE_EMITTER_ARA, type-reference=c64_0_0_1d84467E19_1_SNA  # Consecutive cycle count
      namespaces:
        symbol props CR_Types_Namespace
    CR_RR_Data_Qual_ST3: type-emitter=TYPE_EMITTER_ARA, type-reference=c08_Sens_Data_Qual_ST3  # Status ID representing the current quality level of the sensor
      namespaces:
        symbol props CR_Types_Namespace
    CR_RR_Detection_ST3: type-emitter=TYPE_EMITTER_ARA, type-reference=ARR_CR_RR_Detection_ST3
      namespaces:
        symbol props CR_Types_Namespace
    CR_RR_Dist_RadVelo_Cov_ST3: type-emitter=TYPE_EMITTER_ARA, type-reference=c08_m_sq_p_s_m0d01_p0d01_0d00008  # Covariance of the distance and radial velocity dimension
      namespaces:
        symbol props CR_Types_Namespace
    CR_RR_Dist_Range__ST3: type-emitter=TYPE_EMITTER_ARA, type-reference=c16_m_0_500_0d1  # Upper limit of the sensor's range ambiguity domain
      namespaces:
        symbol props CR_Types_Namespace
    CR_RR_Dtct_SNR_Err_ST3: type-emitter=TYPE_EMITTER_ARA, type-reference=c08_dB_0_5_0d02
      namespaces:
        symbol props CR_Types_Namespace
    CR_RR_Dtctn_Ambgt_ID_ST3: type-emitter=TYPE_EMITTER_ARA, type-reference=c16_0_3000_1
      namespaces:
        symbol props CR_Types_Namespace
    CR_RR_Dtctn_Ambgt_Probb_ST3: type-emitter=TYPE_EMITTER_ARA, type-reference=c08_perc_0_100_1
      namespaces:
        symbol props CR_Types_Namespace
    CR_RR_Dtctn_Azi_Qual_ST3: type-emitter=TYPE_EMITTER_ARA, type-reference=c08_0_100_1
      namespaces:
        symbol props CR_Types_Namespace
    CR_RR_Dtctn_Azi_ST3: type-emitter=TYPE_EMITTER_ARA, type-reference=c16_rad_m1d571_1d57_0d0001745
      namespaces:
        symbol props CR_Types_Namespace
    CR_RR_Dtctn_Azi_StdDev_ST3: type-emitter=TYPE_EMITTER_ARA, type-reference=c08_rad_0_0d044323_0d0001745
      namespaces:
        symbol props CR_Types_Namespace
    CR_RR_Dtctn_Dist_Qual_ST3: type-emitter=TYPE_EMITTER_ARA, type-reference=c08_0_100_1
      namespaces:
        symbol props CR_Types_Namespace
    CR_RR_Dtctn_Dist_ST3: type-emitter=TYPE_EMITTER_ARA, type-reference=c32_m_0_500_0d001
      namespaces:
        symbol props CR_Types_Namespace
    CR_RR_Dtctn_Dist_StdDev_ST3: type-emitter=TYPE_EMITTER_ARA, type-reference=c08_m_0_1d02_0d004_no_SNA
      namespaces:
        symbol props CR_Types_Namespace
    CR_RR_Dtctn_Elev_Qual_ST3: type-emitter=TYPE_EMITTER_ARA, type-reference=c08_0_100_1
      namespaces:
        symbol props CR_Types_Namespace
    CR_RR_Dtctn_Elev_ST3: type-emitter=TYPE_EMITTER_ARA, type-reference=c16_rad_m1d571_1d57_0d0001745
      namespaces:
        symbol props CR_Types_Namespace
    CR_RR_Dtctn_Elev_StdDev_ST3: type-emitter=TYPE_EMITTER_ARA, type-reference=c08_rad_0_0d0886714_0d0001745
      namespaces:
        symbol props CR_Types_Namespace
    CR_RR_Dtctn_Existence_Prob_ST3: type-emitter=TYPE_EMITTER_ARA, type-reference=c08_perc_0_100_1
      namespaces:
        symbol props CR_Types_Namespace
    CR_RR_Dtctn_FreeSp_Probb_ST3: type-emitter=TYPE_EMITTER_ARA, type-reference=c08_perc_0_100_1
      namespaces:
        symbol props CR_Types_Namespace
    CR_RR_Dtctn_ID_Part1_ST3: type-emitter=TYPE_EMITTER_ARA, type-reference=c64_0_0_1d84467E19_1_SNA
      namespaces:
        symbol props CR_Types_Namespace
    CR_RR_Dtctn_ID_Part2_ST3: type-emitter=TYPE_EMITTER_ARA, type-reference=c64_0_0_1d84467E19_1_SNA
      namespaces:
        symbol props CR_Types_Namespace
    CR_RR_Dtctn_MaskAnglSect_Azi_ST3: type-emitter=TYPE_EMITTER_ARA, type-reference=c08_rad_0_3d1416_0d01232_no_SNA
      namespaces:
        symbol props CR_Types_Namespace
    CR_RR_Dtctn_MaskAnglSect_Elev_ST3: type-emitter=TYPE_EMITTER_ARA, type-reference=c08_rad_0_3d1416_0d01232_no_SNA
      namespaces:
        symbol props CR_Types_Namespace
    CR_RR_Dtctn_Meas_Model_ST3: type-emitter=TYPE_EMITTER_ARA, type-reference=c08_Sens_MeasModel_ST3
      namespaces:
        symbol props CR_Types_Namespace
    CR_RR_Dtctn_Micro_Doppler_Val_ST3: type-emitter=TYPE_EMITTER_ARA, type-reference=c08_0_to_3_1_SNA_255
      namespaces:
        symbol props CR_Types_Namespace
    CR_RR_Dtctn_MultiTrgt_Probb_ST3: type-emitter=TYPE_EMITTER_ARA, type-reference=c08_perc_0_100_1
      namespaces:
        symbol props CR_Types_Namespace
    CR_RR_Dtctn_PeakDtct_Thrsld_ST3: type-emitter=TYPE_EMITTER_ARA, type-reference=c08_dB_0_20_0d1
      namespaces:
        symbol props CR_Types_Namespace
    CR_RR_Dtctn_RCS_Err_ST3: type-emitter=TYPE_EMITTER_ARA, type-reference=c08_dBsm_0_2d54_0d01
      namespaces:
        symbol props CR_Types_Namespace
    CR_RR_Dtctn_RCS_ST3: type-emitter=TYPE_EMITTER_ARA, type-reference=c16_dBsm_m100_p100_0d0035
      namespaces:
        symbol props CR_Types_Namespace
    CR_RR_Dtctn_RadRelVelo_Ambgt_Resolv_ST3: type-emitter=TYPE_EMITTER_ARA, type-reference=c02_Fls_Tru
      namespaces:
        symbol props CR_Types_Namespace
    CR_RR_Dtctn_RadRelVelo_ST3: type-emitter=TYPE_EMITTER_ARA, type-reference=c32_m_per_s_m200_100_0d001
      namespaces:
        symbol props CR_Types_Namespace
    CR_RR_Dtctn_RadRelVelo_StdDev_ST3: type-emitter=TYPE_EMITTER_ARA, type-reference=c08_m_p_s_0_0d663_0d0026_No_SNA
      namespaces:
        symbol props CR_Types_Namespace
    CR_RR_Dtctn_RadVelo_Qual_ST3: type-emitter=TYPE_EMITTER_ARA, type-reference=c08_0_100_1
      namespaces:
        symbol props CR_Types_Namespace
    CR_RR_Dtctn_RxSig_Strength_ST3: type-emitter=TYPE_EMITTER_ARA, type-reference=c08_dB_m254_0_1
      namespaces:
        symbol props CR_Types_Namespace
    CR_RR_Dtctn_SNR_ST3: type-emitter=TYPE_EMITTER_ARA, type-reference=c08_dB_0_50_0d2
      namespaces:
        symbol props CR_Types_Namespace
    CR_RR_Dtctn_Stat_ST3: type-emitter=TYPE_EMITTER_ARA, type-reference=c08_Sens_Dtctn_Stat_ST3  # Current status of the sensor. Each number corresponds to a specific state
      namespaces:
        symbol props CR_Types_Namespace
    CR_RR_Dtctn_StaticObj_Stat_ST3: type-emitter=TYPE_EMITTER_ARA, type-reference=c02_Fls_Tru
      namespaces:
        symbol props CR_Types_Namespace
    CR_RR_ElevAngl_LowLmt_ST3: type-emitter=TYPE_EMITTER_ARA, type-reference=c8_rad_m1d404_0_0d006  # Upper limit of the sensor's unambigious elevation domain
      namespaces:
        symbol props CR_Types_Namespace
    CR_RR_ElevAngl_UpLmt_ST3: type-emitter=TYPE_EMITTER_ARA, type-reference=c8_rad_0_1d404_0d006  # Lower limit of the sensor's unambigious elevation domain
      namespaces:
        symbol props CR_Types_Namespace
    CR_RR_Gen_Header_ST3: type-emitter=TYPE_EMITTER_ARA, type-reference=REC_CR_RR_Gen_Header_ST3
      namespaces:
        symbol props CR_Types_Namespace
    CR_RR_Interface_CyclTime_ST3: type-emitter=TYPE_EMITTER_ARA, type-reference=c32_ms_0_4294967294_1  # The current cycle time of the sensor
      namespaces:
        symbol props CR_Types_Namespace
    CR_RR_Interface_CyclTime_Var_ST3: type-emitter=TYPE_EMITTER_ARA, type-reference=c08_perc_0_100_1  # The current variation of the cycle time of the sensor
      namespaces:
        symbol props CR_Types_Namespace
    CR_RR_Interface_ID_ST3: type-emitter=TYPE_EMITTER_ARA, type-reference=c08_0_254_1  # Radar interface ID
      namespaces:
        symbol props CR_Types_Namespace
    CR_RR_LowDist_Dtctn_Indicator_ST3: type-emitter=TYPE_EMITTER_ARA, type-reference=c08_perc_0_100_1  # Probability of a low distance detection
      namespaces:
        symbol props CR_Types_Namespace
    CR_RR_MaxDtctn_ST3: type-emitter=TYPE_EMITTER_ARA, type-reference=c16_0_6000_1  # Maximum number of detections that could be processed by the sensor
      namespaces:
        symbol props CR_Types_Namespace
    CR_RR_Meas_Dur_ST3: type-emitter=TYPE_EMITTER_ARA, type-reference=c16_ms_0_65534_1  # Duration of the measurement time period of this frame
      namespaces:
        symbol props CR_Types_Namespace
    CR_RR_Meas_TmStmp_ST3: type-emitter=TYPE_EMITTER_ARA, type-reference=c64_ms_1_1d84467E19_1  # Timestamp of this measurment
      namespaces:
        symbol props CR_Types_Namespace
    CR_RR_Moduln_Md_ST3: type-emitter=TYPE_EMITTER_ARA, type-reference=c08_Sens_Moduln_Md_ST3  # Current modulation mode of the sensor. Each number corresponds to a specific state
      namespaces:
        symbol props CR_Types_Namespace
    CR_RR_RadVelo_LowLmt_ST3: type-emitter=TYPE_EMITTER_ARA, type-reference=c16_m_per_s_m130_0_0d01  # Lower limit of the sensor's unambigious radial velocity range
      namespaces:
        symbol props CR_Types_Namespace
    CR_RR_RadVelo_UpLmt_ST3: type-emitter=TYPE_EMITTER_ARA, type-reference=c16_m_per_s_0_130_0d01  # Upper limit of the sensor's unambigious radial velocity range
      namespaces:
        symbol props CR_Types_Namespace
    CR_RR_Radar_Header_ST3: type-emitter=TYPE_EMITTER_ARA, type-reference=REC_CR_RR_Radar_Header_ST3
      namespaces:
        symbol props CR_Types_Namespace
    CR_RR_SHI_Header_ST3: type-emitter=TYPE_EMITTER_ARA, type-reference=REC_CR_RR_SHI_Header_ST3  # Radar SHI Header
      namespaces:
        symbol props CR_Types_Namespace
    CR_RR_SPI_Header_ST3: type-emitter=TYPE_EMITTER_ARA, type-reference=REC_CR_RR_SPI_Header_ST3  # Sensor Performance Interface Header
      namespaces:
        symbol props CR_Types_Namespace
    CR_RR_SW_VerID_Major_ST3: type-emitter=TYPE_EMITTER_ARA, type-reference=c08_0_254_1  # Sensor software version ID major
      namespaces:
        symbol props CR_Types_Namespace
    CR_RR_SW_VerID_Minor_ST3: type-emitter=TYPE_EMITTER_ARA, type-reference=c08_0_254_1  # Sensor software version ID minor
      namespaces:
        symbol props CR_Types_Namespace
    CR_RR_SW_VerID_Patch_ST3: type-emitter=TYPE_EMITTER_ARA, type-reference=c08_0_254_1  # Sensor software version ID patch
      namespaces:
        symbol props CR_Types_Namespace
    CR_RR_Seg_AziAngl_Begin_ST3: type-emitter=TYPE_EMITTER_ARA, type-reference=c10_deg_m180_180_1  # Begin of segment in azimuth
      namespaces:
        symbol props CR_Types_Namespace
    CR_RR_Seg_AziAngl_End_ST3: type-emitter=TYPE_EMITTER_ARA, type-reference=c10_deg_m180_180_1  # End of segment in azimuth
      namespaces:
        symbol props CR_Types_Namespace
    CR_RR_Seg_Blockage_Stat_ST3: type-emitter=TYPE_EMITTER_ARA, type-reference=c03_SegBlock_Stat_ST3  # Segment blockage information
      namespaces:
        symbol props CR_Types_Namespace
    CR_RR_Seg_DetctnRange_Max_ST3: type-emitter=TYPE_EMITTER_ARA, type-reference=c10_m_0_400_0d5  # Maximum real detection range based on reference target
      namespaces:
        symbol props CR_Types_Namespace
    CR_RR_Seg_DetctnRange_Min_ST3: type-emitter=TYPE_EMITTER_ARA, type-reference=c10_m_0_400_0d5  # Minimum real detection range based on reference target
      namespaces:
        symbol props CR_Types_Namespace
    CR_RR_Seg_ElevAngl_Begin_ST3: type-emitter=TYPE_EMITTER_ARA, type-reference=c10_deg_m180_180_1  # Begin of segment in elevation
      namespaces:
        symbol props CR_Types_Namespace
    CR_RR_Seg_ElevAngl_End_ST3: type-emitter=TYPE_EMITTER_ARA, type-reference=c10_deg_m180_180_1  # End of segement in elevation
      namespaces:
        symbol props CR_Types_Namespace
    CR_RR_Seg_ID_ST3: type-emitter=TYPE_EMITTER_ARA, type-reference=c06_0_32_1  # Unique segment ID
      namespaces:
        symbol props CR_Types_Namespace
    CR_RR_Seg_Range_Gain_RCS_ST3: type-emitter=TYPE_EMITTER_ARA, type-reference=c10_dB_m30_30_0d1  # Reference RCS for reference target
      namespaces:
        symbol props CR_Types_Namespace
    CR_RR_Seg_Range_Gain_ST3: type-emitter=TYPE_EMITTER_ARA, type-reference=c07_perc_0_100_1  # Range gain for segment based on reference target
      namespaces:
        symbol props CR_Types_Namespace
    CR_RR_Seg_Redctn_Rsn_Prob_ST3: type-emitter=TYPE_EMITTER_ARA, type-reference=ARR_08_perc_0_100_1_8  # Segment probability for reason for blockage
      namespaces:
        symbol props CR_Types_Namespace
    CR_RR_Seg_Redctn_Rsn_ST3: type-emitter=TYPE_EMITTER_ARA, type-reference=c03_Seg_Reduction_Rsn_ST3  # Segment reason for blockage
      namespaces:
        symbol props CR_Types_Namespace
    CR_RR_Segment_ST3: type-emitter=TYPE_EMITTER_ARA, type-reference=ARR_CR_RR_Segment_ST3  # Radar Segments
      namespaces:
        symbol props CR_Types_Namespace
    CR_RR_Sens_COS_Offset_X_ST3: type-emitter=TYPE_EMITTER_ARA, type-reference=c08_m_0_2k5_0k01_NACPT_ST3  # Sensor coordinate system offset between mounting and antenna plane in x
      namespaces:
        symbol props CR_Types_Namespace
    CR_RR_Sens_COS_Offset_Y_ST3: type-emitter=TYPE_EMITTER_ARA, type-reference=c08_m_0_2k5_0k01_NACPT_ST3  # Sensor coordinate system offset between mounting and antenna plane in y
      namespaces:
        symbol props CR_Types_Namespace
    CR_RR_Sens_COS_Offset_Z_ST3: type-emitter=TYPE_EMITTER_ARA, type-reference=c08_m_0_2k5_0k01_NACPT_ST3  # Sensor coordinate system offset between mounting and antenna plane in z
      namespaces:
        symbol props CR_Types_Namespace
    CR_RR_Sens_Calib_Base_Stat_ST3: type-emitter=TYPE_EMITTER_ARA, type-reference=c02_Sens_Calib_Base_Stat_ST3  # Calibration Base State
      namespaces:
        symbol props CR_Types_Namespace
    CR_RR_Sens_Calib_Corrctn_LowLmt_Azi_ST3: type-emitter=TYPE_EMITTER_ARA, type-reference=c08_deg_m10_p10_0d1_ST3  # Lower limit of correction range in azimuth
      namespaces:
        symbol props CR_Types_Namespace
    CR_RR_Sens_Calib_Corrctn_LowLmt_Elev_ST3: type-emitter=TYPE_EMITTER_ARA, type-reference=c08_deg_m10_p10_0d1_ST3  # Lower limit of correction range in elevation
      namespaces:
        symbol props CR_Types_Namespace
    CR_RR_Sens_Calib_Corrctn_LowLmt_Roll_ST3: type-emitter=TYPE_EMITTER_ARA, type-reference=c08_deg_m10_p10_0d1_ST3  # Lower limit of correction range in elevation
      namespaces:
        symbol props CR_Types_Namespace
    CR_RR_Sens_Calib_Corrctn_Orient_Azi_ST3: type-emitter=TYPE_EMITTER_ARA, type-reference=c08_deg_m10_p10_0d1_ST3  # Current sensor mounting after correction in azimuth
      namespaces:
        symbol props CR_Types_Namespace
    CR_RR_Sens_Calib_Corrctn_Orient_Elev_ST3: type-emitter=TYPE_EMITTER_ARA, type-reference=c08_deg_m10_p10_0d1_ST3  # Current sensor mounting after correction in elevation
      namespaces:
        symbol props CR_Types_Namespace
    CR_RR_Sens_Calib_Corrctn_Orient_Roll_ST3: type-emitter=TYPE_EMITTER_ARA, type-reference=c08_deg_m10_p10_0d1_ST3  # Current sensor mounting after correction in roll
      namespaces:
        symbol props CR_Types_Namespace
    CR_RR_Sens_Calib_Corrctn_UpLmt_Azi_ST3: type-emitter=TYPE_EMITTER_ARA, type-reference=c08_deg_m10_p10_0d1_ST3  # Upper limit of correction range in azimuth
      namespaces:
        symbol props CR_Types_Namespace
    CR_RR_Sens_Calib_Corrctn_UpLmt_Elev_ST3: type-emitter=TYPE_EMITTER_ARA, type-reference=c08_deg_m10_p10_0d1_ST3  # Upper limit of correction range in elevation
      namespaces:
        symbol props CR_Types_Namespace
    CR_RR_Sens_Calib_Corrctn_UpLmt_Roll_ST3: type-emitter=TYPE_EMITTER_ARA, type-reference=c08_deg_m10_p10_0d1_ST3  # Upper limit of correction range in roll
      namespaces:
        symbol props CR_Types_Namespace
    CR_RR_Sens_Calib_Func_Stat_ST3: type-emitter=TYPE_EMITTER_ARA, type-reference=c04_Sens_Calib_Func_Stat_ST3  # Calibration Function State
      namespaces:
        symbol props CR_Types_Namespace
    CR_RR_Sens_Calib_SOC_Stat_ST3: type-emitter=TYPE_EMITTER_ARA, type-reference=c02_Sens_Calib_SOC_Stat_ST3  # Sustained Online Calibration State
      namespaces:
        symbol props CR_Types_Namespace
    CR_RR_Sens_Calib_Valid_Comp_ST3: type-emitter=TYPE_EMITTER_ARA, type-reference=c04_0_15_1_SNA_na  # Number of valid sensor calibration components
      namespaces:
        symbol props CR_Types_Namespace
    CR_RR_Sens_Defect_Dtct_ST3: type-emitter=TYPE_EMITTER_ARA, type-reference=c02_Sens_Defect_Dtct_ST3  # Defect state of sensor
      namespaces:
        symbol props CR_Types_Namespace
    CR_RR_Sens_Defect_Rsn_ST3: type-emitter=TYPE_EMITTER_ARA, type-reference=c03_Sens_Defect_Rsn_ST3  # Reasons of sensor defect
      namespaces:
        symbol props CR_Types_Namespace
    CR_RR_Sens_Diag_Md_ST3: type-emitter=TYPE_EMITTER_ARA, type-reference=c02_Diag_Mode_ST3  # State of sensor diagnostic interface
      namespaces:
        symbol props CR_Types_Namespace
    CR_RR_Sens_Extern_Disturbnc_ST3: type-emitter=TYPE_EMITTER_ARA, type-reference=c02_Sens_Disturbnc_Stat_ST3  # Status of disturbance by electromagentic phenomenon (interference)
      namespaces:
        symbol props CR_Types_Namespace
    CR_RR_Sens_GTS_Offset_ST3: type-emitter=TYPE_EMITTER_ARA, type-reference=c32_ns_0_4294967295_1_noSNA  # Offset time of GTS
      namespaces:
        symbol props CR_Types_Namespace
    CR_RR_Sens_Oprtn_Md_ST3: type-emitter=TYPE_EMITTER_ARA, type-reference=c02_Sens_Oprtn_Md_ST3  # Measuring state of sensor
      namespaces:
        symbol props CR_Types_Namespace
    CR_RR_Sens_Oprtn_Stat_ST3: type-emitter=TYPE_EMITTER_ARA, type-reference=c02_Sens_Oprtn_Stat_ST3  # Overall state of sensor health
      namespaces:
        symbol props CR_Types_Namespace
    CR_RR_Sens_Orient_Azi_ST3: type-emitter=TYPE_EMITTER_ARA, type-reference=c08_deg_m10_p10_0d1_ST3  # Sensor mounting orientation in azimuth
      namespaces:
        symbol props CR_Types_Namespace
    CR_RR_Sens_Orient_Elev_ST3: type-emitter=TYPE_EMITTER_ARA, type-reference=c08_deg_m10_p10_0d1_ST3  # Sensor mounting orientation in elevation
      namespaces:
        symbol props CR_Types_Namespace
    CR_RR_Sens_Orient_Err_Azi_ST3: type-emitter=TYPE_EMITTER_ARA, type-reference=c08_deg_m10_p10_0d1_ST3  # Sensor mounting orientation error in azimuth
      namespaces:
        symbol props CR_Types_Namespace
    CR_RR_Sens_Orient_Err_Elev_ST3: type-emitter=TYPE_EMITTER_ARA, type-reference=c08_deg_m10_p10_0d1_ST3  # Sensor mounting orientation error in elevation
      namespaces:
        symbol props CR_Types_Namespace
    CR_RR_Sens_Orient_Err_Roll_ST3: type-emitter=TYPE_EMITTER_ARA, type-reference=c08_deg_m10_p10_0d1_ST3  # Sensor mounting orientation error in roll
      namespaces:
        symbol props CR_Types_Namespace
    CR_RR_Sens_Orient_Roll_ST3: type-emitter=TYPE_EMITTER_ARA, type-reference=c08_deg_m10_p10_0d1_ST3  # Sensor mounting orientation in roll
      namespaces:
        symbol props CR_Types_Namespace
    CR_RR_Sens_Origin_Pos_Err_X_ST3: type-emitter=TYPE_EMITTER_ARA, type-reference=c08_m_0_2k5_0k01_NACPT_ST3  # Sensor mounting position error in x
      namespaces:
        symbol props CR_Types_Namespace
    CR_RR_Sens_Origin_Pos_Err_Y_ST3: type-emitter=TYPE_EMITTER_ARA, type-reference=c08_m_0_2k5_0k01_NACPT_ST3  # Sensor mounting position error in y
      namespaces:
        symbol props CR_Types_Namespace
    CR_RR_Sens_Origin_Pos_Err_Z_ST3: type-emitter=TYPE_EMITTER_ARA, type-reference=c08_m_0_2k5_0k01_NACPT_ST3  # Sensor mounting position error in z
      namespaces:
        symbol props CR_Types_Namespace
    CR_RR_Sens_Origin_Pos_X_ST3: type-emitter=TYPE_EMITTER_ARA, type-reference=c08_m_0_2k5_0k01_NACPT_ST3  # Sensor mounting position in x
      namespaces:
        symbol props CR_Types_Namespace
    CR_RR_Sens_Origin_Pos_Y_ST3: type-emitter=TYPE_EMITTER_ARA, type-reference=c08_m_0_2k5_0k01_NACPT_ST3  # Sensor mounting position in y
      namespaces:
        symbol props CR_Types_Namespace
    CR_RR_Sens_Origin_Pos_Z_ST3: type-emitter=TYPE_EMITTER_ARA, type-reference=c08_m_0_2k5_0k01_NACPT_ST3  # Sensor mounting position in z
      namespaces:
        symbol props CR_Types_Namespace
    CR_RR_Sens_Radom_Heat_Stat_ST3: type-emitter=TYPE_EMITTER_ARA, type-reference=c02_Sens_Radom_Heat_Stat_ST3  # Status of radom heating driver
      namespaces:
        symbol props CR_Types_Namespace
    CR_RR_Sens_Supp_Vtg_Stat_ST3: type-emitter=TYPE_EMITTER_ARA, type-reference=c02_Sens_SuppVtg_Stat_ST3  # State of supply voltage
      namespaces:
        symbol props CR_Types_Namespace
    CR_RR_Sens_Temp_Stat_ST3: type-emitter=TYPE_EMITTER_ARA, type-reference=c02_Sens_Temp_Stat_ST3  # State of internal sensor ECU temperature
      namespaces:
        symbol props CR_Types_Namespace
    CR_RR_Sens_TmSync_Stat_ST3: type-emitter=TYPE_EMITTER_ARA, type-reference=c02_Sens_TimeSync_Stat_ST3  # Status of GTS time sync
      namespaces:
        symbol props CR_Types_Namespace
    CR_RR_Sens_Total_Seg_Azi_ST3: type-emitter=TYPE_EMITTER_ARA, type-reference=c06_0_32_1  # Total (valid + invalid) number of segments in azimuth
      namespaces:
        symbol props CR_Types_Namespace
    CR_RR_Sens_Total_Seg_Elev_ST3: type-emitter=TYPE_EMITTER_ARA, type-reference=c06_0_32_1  # Total (valid + invalid) number of segments in elevation
      namespaces:
        symbol props CR_Types_Namespace
    CR_RR_Sens_Tx_PwrRedctn_Stat_ST3: type-emitter=TYPE_EMITTER_ARA, type-reference=c02_Sens_TxPwrRedctn_Stat_ST3  # Status of RF transmission
      namespaces:
        symbol props CR_Types_Namespace
    CR_RR_Sens_Valid_InputSignals_Curr_ST3: type-emitter=TYPE_EMITTER_ARA, type-reference=c08_UInt_SNA_na  # Number of currently valid input signals
      namespaces:
        symbol props CR_Types_Namespace
    CR_RR_Sens_Valid_InputSignals_Trgt_ST3: type-emitter=TYPE_EMITTER_ARA, type-reference=c08_UInt_SNA_na  # Number of target valid input signals
      namespaces:
        symbol props CR_Types_Namespace
    CR_RR_Sens_Valid_Seg_Azi_ST3: type-emitter=TYPE_EMITTER_ARA, type-reference=c06_0_32_1  # Valid number of segments in azimuth
      namespaces:
        symbol props CR_Types_Namespace
    CR_RR_Sens_Valid_Seg_Elev_ST3: type-emitter=TYPE_EMITTER_ARA, type-reference=c06_0_32_1  # Valid number of segments in elevation
      namespaces:
        symbol props CR_Types_Namespace
    CR_RR_SensorID_ST3: type-emitter=TYPE_EMITTER_ARA, type-reference=c08_0_254_1  # Sensor ID
      namespaces:
        symbol props CR_Types_Namespace
    CR_RR_ValidDtctn_ST3: type-emitter=TYPE_EMITTER_ARA, type-reference=c16_0_6000_1  # Number of valid detections in this measurement
      namespaces:
        symbol props CR_Types_Namespace
    DC_BOOL: type-emitter=TYPE_EMITTER_ARA, type-reference=bool
      namespaces:
        symbol props TypeRef
    DC_TGC_ProximityLvl: type-emitter=TYPE_EMITTER_ARA, type-reference=uint8_t
      namespaces:
        symbol props CR_Types_Namespace
    ECU_Id_IDC_M_P_ST3: type-emitter=TYPE_EMITTER_ARA, type-reference=uint16_t  # Ignition switch state
      namespaces:
        symbol props TypeRef
    ISw_Stat_ST3: type-emitter=TYPE_EMITTER_ARA, type-reference=c03_ISw_Stat  # Ignition switch state
      namespaces:
        symbol props TypeRef
    KG_StartSw_Psd_ST3: type-emitter=TYPE_EMITTER_ARA, type-reference=DC_BOOL  # Keyless Go start switch pressed
      namespaces:
        symbol props TypeRef
    MRR_AziAngl_LowLmt_ST3: type-emitter=TYPE_EMITTER_ARA, type-reference=c16_rad_m157_0_0d001  # Upper limit of the sensor's unambigious azimuth domain
      namespaces:
        symbol props CR_Types_Namespace
    MRR_AziAngl_UpLmt_ST3: type-emitter=TYPE_EMITTER_ARA, type-reference=c16_rad_0_1d57_0d001  # Lower limit of the sensor's unambigious azimuth domain
      namespaces:
        symbol props CR_Types_Namespace
    MRR_Cycl_Count_ST3: type-emitter=TYPE_EMITTER_ARA, type-reference=c64_0_0_1d84467E19_1_SNA  # Consecutive cycle count
      namespaces:
        symbol props CR_Types_Namespace
    MRR_Data_Qual_ST3: type-emitter=TYPE_EMITTER_ARA, type-reference=c08_Sens_Data_Qual_ST3  # Status ID representing the current quality level of the sensor
      namespaces:
        symbol props CR_Types_Namespace
    MRR_Detection_ST3: type-emitter=TYPE_EMITTER_ARA, type-reference=ARR_MRR_Detection_ST3
      namespaces:
        symbol props CR_Types_Namespace
    MRR_Dist_RadVelo_Cov_ST3: type-emitter=TYPE_EMITTER_ARA, type-reference=c08_m_sq_p_s_m0d01_p0d01_0d00008  # Covariance of the distance and radial velocity dimension
      namespaces:
        symbol props CR_Types_Namespace
    MRR_Dist_Range__ST3: type-emitter=TYPE_EMITTER_ARA, type-reference=c16_m_0_500_0d1  # Upper limit of the sensor's range ambiguity domain
      namespaces:
        symbol props CR_Types_Namespace
    MRR_Dtct_SNR_Err_ST3: type-emitter=TYPE_EMITTER_ARA, type-reference=c08_dB_0_5_0d02
      namespaces:
        symbol props CR_Types_Namespace
    MRR_Dtctn_Ambgt_ID_ST3: type-emitter=TYPE_EMITTER_ARA, type-reference=c16_0_3000_1
      namespaces:
        symbol props CR_Types_Namespace
    MRR_Dtctn_Ambgt_Probb_ST3: type-emitter=TYPE_EMITTER_ARA, type-reference=c08_perc_0_100_1
      namespaces:
        symbol props CR_Types_Namespace
    MRR_Dtctn_Azi_Qual_ST3: type-emitter=TYPE_EMITTER_ARA, type-reference=c08_0_100_1
      namespaces:
        symbol props CR_Types_Namespace
    MRR_Dtctn_Azi_ST3: type-emitter=TYPE_EMITTER_ARA, type-reference=c16_rad_m1d571_1d57_0d0001745
      namespaces:
        symbol props CR_Types_Namespace
    MRR_Dtctn_Azi_StdDev_ST3: type-emitter=TYPE_EMITTER_ARA, type-reference=c08_rad_0_0d044323_0d0001745
      namespaces:
        symbol props CR_Types_Namespace
    MRR_Dtctn_Dist_Qual_ST3: type-emitter=TYPE_EMITTER_ARA, type-reference=c08_0_100_1
      namespaces:
        symbol props CR_Types_Namespace
    MRR_Dtctn_Dist_ST3: type-emitter=TYPE_EMITTER_ARA, type-reference=c32_m_0_500_0d001
      namespaces:
        symbol props CR_Types_Namespace
    MRR_Dtctn_Dist_StdDev_ST3: type-emitter=TYPE_EMITTER_ARA, type-reference=c08_m_0_1d02_0d004_no_SNA
      namespaces:
        symbol props CR_Types_Namespace
    MRR_Dtctn_Elev_Qual_ST3: type-emitter=TYPE_EMITTER_ARA, type-reference=c08_0_100_1
      namespaces:
        symbol props CR_Types_Namespace
    MRR_Dtctn_Elev_ST3: type-emitter=TYPE_EMITTER_ARA, type-reference=c16_rad_m1d571_1d57_0d0001745
      namespaces:
        symbol props CR_Types_Namespace
    MRR_Dtctn_Elev_StdDev_ST3: type-emitter=TYPE_EMITTER_ARA, type-reference=c08_rad_0_0d0886714_0d0001745
      namespaces:
        symbol props CR_Types_Namespace
    MRR_Dtctn_Existence_Prob_ST3: type-emitter=TYPE_EMITTER_ARA, type-reference=c08_perc_0_100_1
      namespaces:
        symbol props CR_Types_Namespace
    MRR_Dtctn_FreeSp_Probb_ST3: type-emitter=TYPE_EMITTER_ARA, type-reference=c08_perc_0_100_1
      namespaces:
        symbol props CR_Types_Namespace
    MRR_Dtctn_ID_Part1_ST3: type-emitter=TYPE_EMITTER_ARA, type-reference=c64_0_0_1d84467E19_1_SNA
      namespaces:
        symbol props CR_Types_Namespace
    MRR_Dtctn_ID_Part2_ST3: type-emitter=TYPE_EMITTER_ARA, type-reference=c64_0_0_1d84467E19_1_SNA
      namespaces:
        symbol props CR_Types_Namespace
    MRR_Dtctn_MaskAnglSect_Azi_ST3: type-emitter=TYPE_EMITTER_ARA, type-reference=c08_rad_0_3d1416_0d01232_no_SNA
      namespaces:
        symbol props CR_Types_Namespace
    MRR_Dtctn_MaskAnglSect_Elev_ST3: type-emitter=TYPE_EMITTER_ARA, type-reference=c08_rad_0_3d1416_0d01232_no_SNA
      namespaces:
        symbol props CR_Types_Namespace
    MRR_Dtctn_Meas_Model_ST3: type-emitter=TYPE_EMITTER_ARA, type-reference=c08_Sens_MeasModel_ST3
      namespaces:
        symbol props CR_Types_Namespace
    MRR_Dtctn_Micro_Doppler_Val_ST3: type-emitter=TYPE_EMITTER_ARA, type-reference=c08_0_to_3_1_SNA_255
      namespaces:
        symbol props CR_Types_Namespace
    MRR_Dtctn_MultiTrgt_Probb_ST3: type-emitter=TYPE_EMITTER_ARA, type-reference=c08_perc_0_100_1
      namespaces:
        symbol props CR_Types_Namespace
    MRR_Dtctn_PeakDtct_Thrsld_ST3: type-emitter=TYPE_EMITTER_ARA, type-reference=c08_dB_0_20_0d1
      namespaces:
        symbol props CR_Types_Namespace
    MRR_Dtctn_RCS_Err_ST3: type-emitter=TYPE_EMITTER_ARA, type-reference=c08_dBsm_0_2d54_0d01
      namespaces:
        symbol props CR_Types_Namespace
    MRR_Dtctn_RCS_ST3: type-emitter=TYPE_EMITTER_ARA, type-reference=c16_dBsm_m100_p100_0d0035
      namespaces:
        symbol props CR_Types_Namespace
    MRR_Dtctn_RadRelVelo_Ambgt_Resolv_ST3: type-emitter=TYPE_EMITTER_ARA, type-reference=c02_Fls_Tru
      namespaces:
        symbol props CR_Types_Namespace
    MRR_Dtctn_RadRelVelo_ST3: type-emitter=TYPE_EMITTER_ARA, type-reference=c32_m_per_s_m200_100_0d001
      namespaces:
        symbol props CR_Types_Namespace
    MRR_Dtctn_RadRelVelo_StdDev_ST3: type-emitter=TYPE_EMITTER_ARA, type-reference=c08_m_p_s_0_0d663_0d0026_No_SNA
      namespaces:
        symbol props CR_Types_Namespace
    MRR_Dtctn_RadVelo_Qual_ST3: type-emitter=TYPE_EMITTER_ARA, type-reference=c08_0_100_1
      namespaces:
        symbol props CR_Types_Namespace
    MRR_Dtctn_RxSig_Strength_ST3: type-emitter=TYPE_EMITTER_ARA, type-reference=c08_dB_m254_0_1
      namespaces:
        symbol props CR_Types_Namespace
    MRR_Dtctn_SNR_ST3: type-emitter=TYPE_EMITTER_ARA, type-reference=c08_dB_0_50_0d2
      namespaces:
        symbol props CR_Types_Namespace
    MRR_Dtctn_Stat_ST3: type-emitter=TYPE_EMITTER_ARA, type-reference=c08_Sens_Dtctn_Stat_ST3  # Current status of the sensor. Each number corresponds to a specific state
      namespaces:
        symbol props CR_Types_Namespace
    MRR_Dtctn_StaticObj_Stat_ST3: type-emitter=TYPE_EMITTER_ARA, type-reference=c02_Fls_Tru
      namespaces:
        symbol props CR_Types_Namespace
    MRR_ElevAngl_LowLmt_ST3: type-emitter=TYPE_EMITTER_ARA, type-reference=c8_rad_m1d404_0_0d006  # Upper limit of the sensor's unambigious elevation domain
      namespaces:
        symbol props CR_Types_Namespace
    MRR_ElevAngl_UpLmt_ST3: type-emitter=TYPE_EMITTER_ARA, type-reference=c8_rad_0_1d404_0d006  # Lower limit of the sensor's unambigious elevation domain
      namespaces:
        symbol props CR_Types_Namespace
    MRR_Gen_Header_ST3: type-emitter=TYPE_EMITTER_ARA, type-reference=REC_MRR_Gen_Header_ST3
      namespaces:
        symbol props CR_Types_Namespace
    MRR_Interface_CyclTime_ST3: type-emitter=TYPE_EMITTER_ARA, type-reference=c32_ms_0_4294967294_1  # The current cycle time of the sensor
      namespaces:
        symbol props CR_Types_Namespace
    MRR_Interface_CyclTime_Var_ST3: type-emitter=TYPE_EMITTER_ARA, type-reference=c08_perc_0_100_1  # The current variation of the cycle time of the sensor
      namespaces:
        symbol props CR_Types_Namespace
    MRR_Interface_ID_ST3: type-emitter=TYPE_EMITTER_ARA, type-reference=c08_0_254_1  # Radar interface ID
      namespaces:
        symbol props CR_Types_Namespace
    MRR_LowDist_Dtctn_Indicator_ST3: type-emitter=TYPE_EMITTER_ARA, type-reference=c08_perc_0_100_1  # Probability of a low distance detection
      namespaces:
        symbol props CR_Types_Namespace
    MRR_MaxDtctn_ST3: type-emitter=TYPE_EMITTER_ARA, type-reference=c16_0_6000_1  # Maximum number of detections that could be processed by the sensor
      namespaces:
        symbol props CR_Types_Namespace
    MRR_Meas_Dur_ST3: type-emitter=TYPE_EMITTER_ARA, type-reference=c16_ms_0_65534_1  # Duration of the measurement time period of this frame
      namespaces:
        symbol props CR_Types_Namespace
    MRR_Meas_TmStmp_ST3: type-emitter=TYPE_EMITTER_ARA, type-reference=c64_ms_1_1d84467E19_1  # Timestamp of this measurment
      namespaces:
        symbol props CR_Types_Namespace
    MRR_Moduln_Md_ST3: type-emitter=TYPE_EMITTER_ARA, type-reference=c08_Sens_Moduln_Md_ST3  # Current modulation mode of the sensor. Each number corresponds to a specific state
      namespaces:
        symbol props CR_Types_Namespace
    MRR_RadVelo_LowLmt_ST3: type-emitter=TYPE_EMITTER_ARA, type-reference=c16_m_per_s_m130_0_0d01  # Lower limit of the sensor's unambigious radial velocity range
      namespaces:
        symbol props CR_Types_Namespace
    MRR_RadVelo_UpLmt_ST3: type-emitter=TYPE_EMITTER_ARA, type-reference=c16_m_per_s_0_130_0d01  # Upper limit of the sensor's unambigious radial velocity range
      namespaces:
        symbol props CR_Types_Namespace
    MRR_Radar_Header_ST3: type-emitter=TYPE_EMITTER_ARA, type-reference=REC_MRR_Radar_Header_ST3
      namespaces:
        symbol props CR_Types_Namespace
    MRR_SHI_Header_ST3: type-emitter=TYPE_EMITTER_ARA, type-reference=REC_MRR_SHI_Header_ST3  # Radar SHI Header
      namespaces:
        symbol props CR_Types_Namespace
    MRR_SPI_Header_ST3: type-emitter=TYPE_EMITTER_ARA, type-reference=REC_MRR_SPI_Header_ST3  # Sensor Performance Interface Header
      namespaces:
        symbol props CR_Types_Namespace
    MRR_SW_VerID_Major_ST3: type-emitter=TYPE_EMITTER_ARA, type-reference=c08_0_254_1  # Sensor software version ID major
      namespaces:
        symbol props CR_Types_Namespace
    MRR_SW_VerID_Minor_ST3: type-emitter=TYPE_EMITTER_ARA, type-reference=c08_0_254_1  # Sensor software version ID minor
      namespaces:
        symbol props CR_Types_Namespace
    MRR_SW_VerID_Patch_ST3: type-emitter=TYPE_EMITTER_ARA, type-reference=c08_0_254_1  # Sensor software version ID patch
      namespaces:
        symbol props CR_Types_Namespace
    MRR_Seg_AziAngl_Begin_ST3: type-emitter=TYPE_EMITTER_ARA, type-reference=c10_deg_m180_180_1  # Begin of segment in azimuth
      namespaces:
        symbol props CR_Types_Namespace
    MRR_Seg_AziAngl_End_ST3: type-emitter=TYPE_EMITTER_ARA, type-reference=c10_deg_m180_180_1  # End of segment in azimuth
      namespaces:
        symbol props CR_Types_Namespace
    MRR_Seg_Blockage_Stat_ST3: type-emitter=TYPE_EMITTER_ARA, type-reference=c03_SegBlock_Stat_ST3  # Segment blockage information
      namespaces:
        symbol props CR_Types_Namespace
    MRR_Seg_DetctnRange_Max_ST3: type-emitter=TYPE_EMITTER_ARA, type-reference=c10_m_0_400_0d5  # Maximum real detection range based on reference target
      namespaces:
        symbol props CR_Types_Namespace
    MRR_Seg_DetctnRange_Min_ST3: type-emitter=TYPE_EMITTER_ARA, type-reference=c10_m_0_400_0d5  # Minimum real detection range based on reference target
      namespaces:
        symbol props CR_Types_Namespace
    MRR_Seg_ElevAngl_Begin_ST3: type-emitter=TYPE_EMITTER_ARA, type-reference=c10_deg_m180_180_1  # Begin of segment in elevation
      namespaces:
        symbol props CR_Types_Namespace
    MRR_Seg_ElevAngl_End_ST3: type-emitter=TYPE_EMITTER_ARA, type-reference=c10_deg_m180_180_1  # End of segement in elevation
      namespaces:
        symbol props CR_Types_Namespace
    MRR_Seg_ID_ST3: type-emitter=TYPE_EMITTER_ARA, type-reference=c06_0_32_1  # Unique segment ID
      namespaces:
        symbol props CR_Types_Namespace
    MRR_Seg_Range_Gain_RCS_ST3: type-emitter=TYPE_EMITTER_ARA, type-reference=c10_dB_m30_30_0d1  # Reference RCS for reference target
      namespaces:
        symbol props CR_Types_Namespace
    MRR_Seg_Range_Gain_ST3: type-emitter=TYPE_EMITTER_ARA, type-reference=c07_perc_0_100_1  # Range gain for segment based on reference target
      namespaces:
        symbol props CR_Types_Namespace
    MRR_Seg_Redctn_Rsn_Prob_ST3: type-emitter=TYPE_EMITTER_ARA, type-reference=ARR_08_perc_0_100_1_8  # Segment probability for reason for blockage
      namespaces:
        symbol props CR_Types_Namespace
    MRR_Seg_Redctn_Rsn_ST3: type-emitter=TYPE_EMITTER_ARA, type-reference=c03_Seg_Reduction_Rsn_ST3  # Segment reason for blockage
      namespaces:
        symbol props CR_Types_Namespace
    MRR_Segment_ST3: type-emitter=TYPE_EMITTER_ARA, type-reference=ARR_MRR_Segment_ST3  # Radar Segments
      namespaces:
        symbol props CR_Types_Namespace
    MRR_Sens_COS_Offset_X_ST3: type-emitter=TYPE_EMITTER_ARA, type-reference=c08_m_0_2k5_0k01_NACPT_ST3  # Sensor coordinate system offset between mounting and antenna plane in x
      namespaces:
        symbol props CR_Types_Namespace
    MRR_Sens_COS_Offset_Y_ST3: type-emitter=TYPE_EMITTER_ARA, type-reference=c08_m_0_2k5_0k01_NACPT_ST3  # Sensor coordinate system offset between mounting and antenna plane in y
      namespaces:
        symbol props CR_Types_Namespace
    MRR_Sens_COS_Offset_Z_ST3: type-emitter=TYPE_EMITTER_ARA, type-reference=c08_m_0_2k5_0k01_NACPT_ST3  # Sensor coordinate system offset between mounting and antenna plane in z
      namespaces:
        symbol props CR_Types_Namespace
    MRR_Sens_Calib_Base_Stat_ST3: type-emitter=TYPE_EMITTER_ARA, type-reference=c02_Sens_Calib_Base_Stat_ST3  # Calibration Base State
      namespaces:
        symbol props CR_Types_Namespace
    MRR_Sens_Calib_Corrctn_LowLmt_Azi_ST3: type-emitter=TYPE_EMITTER_ARA, type-reference=c08_deg_m10_p10_0d1_ST3  # Lower limit of correction range in azimuth
      namespaces:
        symbol props CR_Types_Namespace
    MRR_Sens_Calib_Corrctn_LowLmt_Elev_ST3: type-emitter=TYPE_EMITTER_ARA, type-reference=c08_deg_m10_p10_0d1_ST3  # Lower limit of correction range in elevation
      namespaces:
        symbol props CR_Types_Namespace
    MRR_Sens_Calib_Corrctn_LowLmt_Roll_ST3: type-emitter=TYPE_EMITTER_ARA, type-reference=c08_deg_m10_p10_0d1_ST3  # Lower limit of correction range in elevation
      namespaces:
        symbol props CR_Types_Namespace
    MRR_Sens_Calib_Corrctn_Orient_Azi_ST3: type-emitter=TYPE_EMITTER_ARA, type-reference=c08_deg_m10_p10_0d1_ST3  # Current sensor mounting after correction in azimuth
      namespaces:
        symbol props CR_Types_Namespace
    MRR_Sens_Calib_Corrctn_Orient_Elev_ST3: type-emitter=TYPE_EMITTER_ARA, type-reference=c08_deg_m10_p10_0d1_ST3  # Current sensor mounting after correction in elevation
      namespaces:
        symbol props CR_Types_Namespace
    MRR_Sens_Calib_Corrctn_Orient_Roll_ST3: type-emitter=TYPE_EMITTER_ARA, type-reference=c08_deg_m10_p10_0d1_ST3  # Current sensor mounting after correction in roll
      namespaces:
        symbol props CR_Types_Namespace
    MRR_Sens_Calib_Corrctn_UpLmt_Azi_ST3: type-emitter=TYPE_EMITTER_ARA, type-reference=c08_deg_m10_p10_0d1_ST3  # Upper limit of correction range in azimuth
      namespaces:
        symbol props CR_Types_Namespace
    MRR_Sens_Calib_Corrctn_UpLmt_Elev_ST3: type-emitter=TYPE_EMITTER_ARA, type-reference=c08_deg_m10_p10_0d1_ST3  # Upper limit of correction range in elevation
      namespaces:
        symbol props CR_Types_Namespace
    MRR_Sens_Calib_Corrctn_UpLmt_Roll_ST3: type-emitter=TYPE_EMITTER_ARA, type-reference=c08_deg_m10_p10_0d1_ST3  # Upper limit of correction range in roll
      namespaces:
        symbol props CR_Types_Namespace
    MRR_Sens_Calib_Func_Stat_ST3: type-emitter=TYPE_EMITTER_ARA, type-reference=c04_Sens_Calib_Func_Stat_ST3  # Calibration Function State
      namespaces:
        symbol props CR_Types_Namespace
    MRR_Sens_Calib_SOC_Stat_ST3: type-emitter=TYPE_EMITTER_ARA, type-reference=c02_Sens_Calib_SOC_Stat_ST3  # Sustained Online Calibration State
      namespaces:
        symbol props CR_Types_Namespace
    MRR_Sens_Calib_Valid_Comp_ST3: type-emitter=TYPE_EMITTER_ARA, type-reference=c04_0_15_1_SNA_na  # Number of valid sensor calibration components
      namespaces:
        symbol props CR_Types_Namespace
    MRR_Sens_Defect_Dtct_ST3: type-emitter=TYPE_EMITTER_ARA, type-reference=c02_Sens_Defect_Dtct_ST3  # Defect state of sensor
      namespaces:
        symbol props CR_Types_Namespace
    MRR_Sens_Defect_Rsn_ST3: type-emitter=TYPE_EMITTER_ARA, type-reference=c03_Sens_Defect_Rsn_ST3  # Reasons of sensor defect
      namespaces:
        symbol props CR_Types_Namespace
    MRR_Sens_Diag_Md_ST3: type-emitter=TYPE_EMITTER_ARA, type-reference=c02_Diag_Mode_ST3  # State of sensor diagnostic interface
      namespaces:
        symbol props CR_Types_Namespace
    MRR_Sens_Extern_Disturbnc_ST3: type-emitter=TYPE_EMITTER_ARA, type-reference=c02_Sens_Disturbnc_Stat_ST3  # Status of disturbance by electromagentic phenomenon (interference)
      namespaces:
        symbol props CR_Types_Namespace
    MRR_Sens_GTS_Offset_ST3: type-emitter=TYPE_EMITTER_ARA, type-reference=c32_ns_0_4294967295_1_noSNA  # Offset time of GTS
      namespaces:
        symbol props CR_Types_Namespace
    MRR_Sens_Oprtn_Md_ST3: type-emitter=TYPE_EMITTER_ARA, type-reference=c02_Sens_Oprtn_Md_ST3  # Measuring state of sensor
      namespaces:
        symbol props CR_Types_Namespace
    MRR_Sens_Oprtn_Stat_ST3: type-emitter=TYPE_EMITTER_ARA, type-reference=c02_Sens_Oprtn_Stat_ST3  # Overall state of sensor health
      namespaces:
        symbol props CR_Types_Namespace
    MRR_Sens_Orient_Azi_ST3: type-emitter=TYPE_EMITTER_ARA, type-reference=c08_deg_m10_p10_0d1_ST3  # Sensor mounting orientation in azimuth
      namespaces:
        symbol props CR_Types_Namespace
    MRR_Sens_Orient_Elev_ST3: type-emitter=TYPE_EMITTER_ARA, type-reference=c08_deg_m10_p10_0d1_ST3  # Sensor mounting orientation in elevation
      namespaces:
        symbol props CR_Types_Namespace
    MRR_Sens_Orient_Err_Azi_ST3: type-emitter=TYPE_EMITTER_ARA, type-reference=c08_deg_m10_p10_0d1_ST3  # Sensor mounting orientation error in azimuth
      namespaces:
        symbol props CR_Types_Namespace
    MRR_Sens_Orient_Err_Elev_ST3: type-emitter=TYPE_EMITTER_ARA, type-reference=c08_deg_m10_p10_0d1_ST3  # Sensor mounting orientation error in elevation
      namespaces:
        symbol props CR_Types_Namespace
    MRR_Sens_Orient_Err_Roll_ST3: type-emitter=TYPE_EMITTER_ARA, type-reference=c08_deg_m10_p10_0d1_ST3  # Sensor mounting orientation error in roll
      namespaces:
        symbol props CR_Types_Namespace
    MRR_Sens_Orient_Roll_ST3: type-emitter=TYPE_EMITTER_ARA, type-reference=c08_deg_m10_p10_0d1_ST3  # Sensor mounting orientation in roll
      namespaces:
        symbol props CR_Types_Namespace
    MRR_Sens_Origin_Pos_Err_X_ST3: type-emitter=TYPE_EMITTER_ARA, type-reference=c08_m_0_2k5_0k01_NACPT_ST3  # Sensor mounting position error in x
      namespaces:
        symbol props CR_Types_Namespace
    MRR_Sens_Origin_Pos_Err_Y_ST3: type-emitter=TYPE_EMITTER_ARA, type-reference=c08_m_0_2k5_0k01_NACPT_ST3  # Sensor mounting position error in y
      namespaces:
        symbol props CR_Types_Namespace
    MRR_Sens_Origin_Pos_Err_Z_ST3: type-emitter=TYPE_EMITTER_ARA, type-reference=c08_m_0_2k5_0k01_NACPT_ST3  # Sensor mounting position error in z
      namespaces:
        symbol props CR_Types_Namespace
    MRR_Sens_Origin_Pos_X_ST3: type-emitter=TYPE_EMITTER_ARA, type-reference=c08_m_0_2k5_0k01_NACPT_ST3  # Sensor mounting position in x
      namespaces:
        symbol props CR_Types_Namespace
    MRR_Sens_Origin_Pos_Y_ST3: type-emitter=TYPE_EMITTER_ARA, type-reference=c08_m_0_2k5_0k01_NACPT_ST3  # Sensor mounting position in y
      namespaces:
        symbol props CR_Types_Namespace
    MRR_Sens_Origin_Pos_Z_ST3: type-emitter=TYPE_EMITTER_ARA, type-reference=c08_m_0_2k5_0k01_NACPT_ST3  # Sensor mounting position in z
      namespaces:
        symbol props CR_Types_Namespace
    MRR_Sens_Radom_Heat_Stat_ST3: type-emitter=TYPE_EMITTER_ARA, type-reference=c02_Sens_Radom_Heat_Stat_ST3  # Status of radom heating driver
      namespaces:
        symbol props CR_Types_Namespace
    MRR_Sens_Supp_Vtg_Stat_ST3: type-emitter=TYPE_EMITTER_ARA, type-reference=c02_Sens_SuppVtg_Stat_ST3  # State of supply voltage
      namespaces:
        symbol props CR_Types_Namespace
    MRR_Sens_Temp_Stat_ST3: type-emitter=TYPE_EMITTER_ARA, type-reference=c02_Sens_Temp_Stat_ST3  # State of internal sensor ECU temperature
      namespaces:
        symbol props CR_Types_Namespace
    MRR_Sens_TmSync_Stat_ST3: type-emitter=TYPE_EMITTER_ARA, type-reference=c02_Sens_TimeSync_Stat_ST3  # Status of GTS time sync
      namespaces:
        symbol props CR_Types_Namespace
    MRR_Sens_Total_Seg_Azi_ST3: type-emitter=TYPE_EMITTER_ARA, type-reference=c06_0_32_1  # Total (valid + invalid) number of segments in azimuth
      namespaces:
        symbol props CR_Types_Namespace
    MRR_Sens_Total_Seg_Elev_ST3: type-emitter=TYPE_EMITTER_ARA, type-reference=c06_0_32_1  # Total (valid + invalid) number of segments in elevation
      namespaces:
        symbol props CR_Types_Namespace
    MRR_Sens_Tx_PwrRedctn_Stat_ST3: type-emitter=TYPE_EMITTER_ARA, type-reference=c02_Sens_TxPwrRedctn_Stat_ST3  # Status of RF transmission
      namespaces:
        symbol props CR_Types_Namespace
    MRR_Sens_Valid_InputSignals_Curr_ST3: type-emitter=TYPE_EMITTER_ARA, type-reference=c08_UInt_SNA_na  # Number of currently valid input signals
      namespaces:
        symbol props CR_Types_Namespace
    MRR_Sens_Valid_InputSignals_Trgt_ST3: type-emitter=TYPE_EMITTER_ARA, type-reference=c08_UInt_SNA_na  # Number of target valid input signals
      namespaces:
        symbol props CR_Types_Namespace
    MRR_Sens_Valid_Seg_Azi_ST3: type-emitter=TYPE_EMITTER_ARA, type-reference=c06_0_32_1  # Valid number of segments in azimuth
      namespaces:
        symbol props CR_Types_Namespace
    MRR_Sens_Valid_Seg_Elev_ST3: type-emitter=TYPE_EMITTER_ARA, type-reference=c06_0_32_1  # Valid number of segments in elevation
      namespaces:
        symbol props CR_Types_Namespace
    MRR_SensorID_ST3: type-emitter=TYPE_EMITTER_ARA, type-reference=c08_0_254_1  # Sensor ID
      namespaces:
        symbol props CR_Types_Namespace
    MRR_ValidDtctn_ST3: type-emitter=TYPE_EMITTER_ARA, type-reference=c16_0_6000_1  # Number of valid detections in this measurement
      namespaces:
        symbol props CR_Types_Namespace
    NwId_Rsrv_ST3: type-emitter=TYPE_EMITTER_ARA, type-reference=uint8_t  # Operating Mode Vehicle
      namespaces:
        symbol props TypeRef
